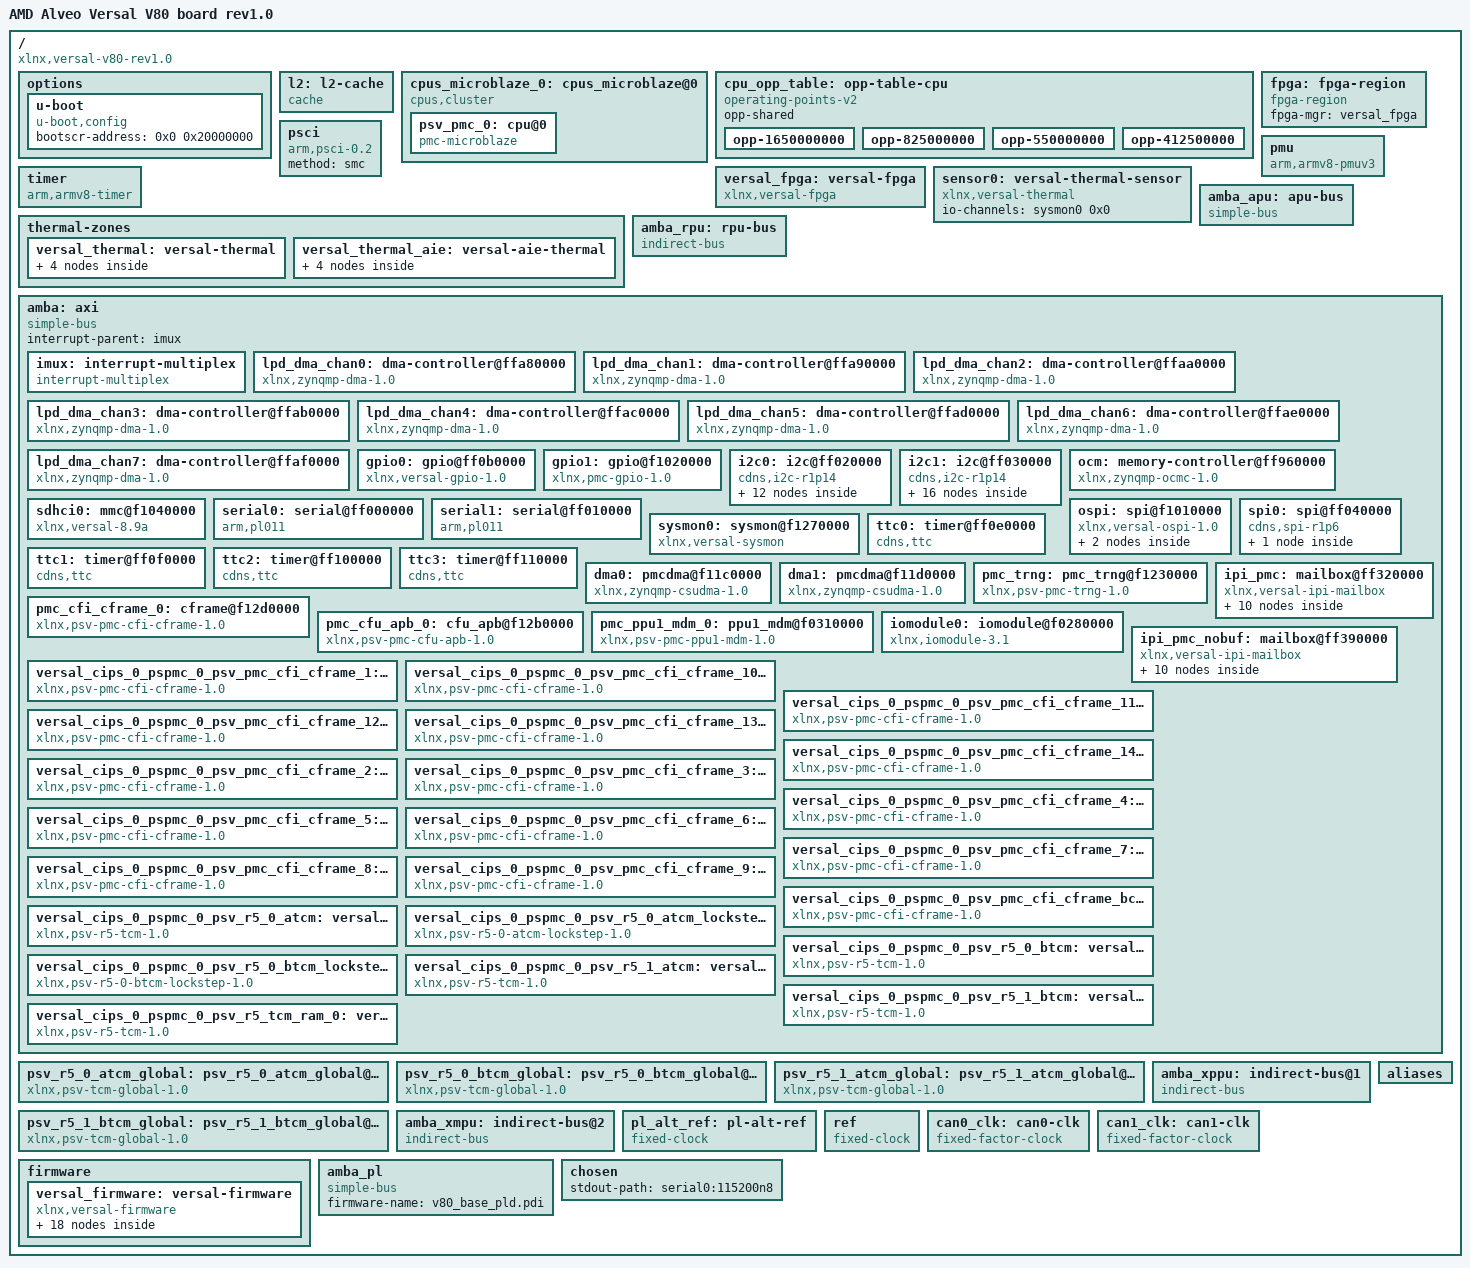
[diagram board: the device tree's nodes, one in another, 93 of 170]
/dts-v1/;
/ {
        compatible = "xlnx,versal-v80-rev1.0", "xlnx,versal";
        #address-cells = <0x2>;
        #size-cells = <0x2>;
        model = "AMD Alveo Versal V80 board rev1.0";
        board = "v80";
        device_id = "xcv80";
        slrcount = <0x3>;
        family = "Versal";
        speed_grade = "2MHP";
        pruned-sdt = <0x1>;

        options {

                u-boot {
                        compatible = "u-boot,config";
                        bootscr-address = <0x0 0x20000000>;
                };
        };

        l2: l2-cache {
                phandle = <0x88>;
                compatible = "cache";
                cache-level = <0x2>;
                cache-size = <0x100000>;
                cache-line-size = <0x40>;
                cache-sets = <0x1000>;
                cache-unified;
        };

        cpus_microblaze_0: cpus_microblaze@0 {
                phandle = <0xb1>;
                #address-cells = <0x1>;
                #size-cells = <0x0>;
                compatible = "cpus,cluster";
                address-map = <0xf0000000 &amba 0xf0000000 0x10000000>,
                 <0xff320000 &ipi_pmc 0xff320000 0x10000>,
                 <0xff390000 &ipi_pmc_nobuf 0xff390000 0x10000>,
                 <0xf0310000 &pmc_ppu1_mdm_0 0xf0310000 0x8000>,
                 <0xf1010000 &ospi 0xf1010000 0x10000>,
                 <0xf1020000 &gpio1 0xf1020000 0x10000>,
                 <0xf1040000 &sdhci0 0xf1040000 0x10000>,
                 <0xf11c0000 &dma0 0xf11c0000 0x10000>,
                 <0xf11d0000 &dma1 0xf11d0000 0x10000>,
                 <0xf1230000 &pmc_trng 0xf1230000 0x10000>,
                 <0xf1270000 &sysmon0 0xf1270000 0x30000>,
                 <0xf12b0000 &pmc_cfu_apb_0 0xf12b0000 0x10000>,
                 <0xf12d0000 &pmc_cfi_cframe_0 0xf12d0000 0x1000>,
                 <0xf12d2000 &versal_cips_0_pspmc_0_psv_pmc_cfi_cframe_1 0xf12d2000 0x1000>,
                 <0xf12d4000 &versal_cips_0_pspmc_0_psv_pmc_cfi_cframe_2 0xf12d4000 0x1000>,
                 <0xf12d6000 &versal_cips_0_pspmc_0_psv_pmc_cfi_cframe_3 0xf12d6000 0x1000>,
                 <0xf12d8000 &versal_cips_0_pspmc_0_psv_pmc_cfi_cframe_4 0xf12d8000 0x1000>,
                 <0xf12da000 &versal_cips_0_pspmc_0_psv_pmc_cfi_cframe_5 0xf12da000 0x1000>,
                 <0xf12dc000 &versal_cips_0_pspmc_0_psv_pmc_cfi_cframe_6 0xf12dc000 0x1000>,
                 <0xf12de000 &versal_cips_0_pspmc_0_psv_pmc_cfi_cframe_7 0xf12de000 0x1000>,
                 <0xf12e0000 &versal_cips_0_pspmc_0_psv_pmc_cfi_cframe_8 0xf12e0000 0x1000>,
                 <0xf12e2000 &versal_cips_0_pspmc_0_psv_pmc_cfi_cframe_9 0xf12e2000 0x1000>,
                 <0xf12e4000 &versal_cips_0_pspmc_0_psv_pmc_cfi_cframe_10 0xf12e4000 0x1000>,
                 <0xf12e6000 &versal_cips_0_pspmc_0_psv_pmc_cfi_cframe_11 0xf12e6000 0x1000>,
                 <0xf12e8000 &versal_cips_0_pspmc_0_psv_pmc_cfi_cframe_12 0xf12e8000 0x1000>,
                 <0xf12ea000 &versal_cips_0_pspmc_0_psv_pmc_cfi_cframe_13 0xf12ea000 0x1000>,
                 <0xf12ec000 &versal_cips_0_pspmc_0_psv_pmc_cfi_cframe_14 0xf12ec000 0x1000>,
                 <0xf12ee000 &versal_cips_0_pspmc_0_psv_pmc_cfi_cframe_bcast 0xf12ee000 0x1000>,
                 <0xff000000 &serial0 0xff000000 0x10000>,
                 <0xff010000 &serial1 0xff010000 0x10000>,
                 <0xff020000 &i2c0 0xff020000 0x10000>,
                 <0xff030000 &i2c1 0xff030000 0x10000>,
                 <0xff040000 &spi0 0xff040000 0x10000>,
                 <0xff0b0000 &gpio0 0xff0b0000 0x10000>,
                 <0xff0e0000 &ttc0 0xff0e0000 0x10000>,
                 <0xff0f0000 &ttc1 0xff0f0000 0x10000>,
                 <0xff100000 &ttc2 0xff100000 0x10000>,
                 <0xff110000 &ttc3 0xff110000 0x10000>,
                 <0xffa80000 &lpd_dma_chan0 0xffa80000 0x10000>,
                 <0xffa90000 &lpd_dma_chan1 0xffa90000 0x10000>,
                 <0xffaa0000 &lpd_dma_chan2 0xffaa0000 0x10000>,
                 <0xffab0000 &lpd_dma_chan3 0xffab0000 0x10000>,
                 <0xffac0000 &lpd_dma_chan4 0xffac0000 0x10000>,
                 <0xffad0000 &lpd_dma_chan5 0xffad0000 0x10000>,
                 <0xffae0000 &lpd_dma_chan6 0xffae0000 0x10000>,
                 <0xffaf0000 &lpd_dma_chan7 0xffaf0000 0x10000>,
                 <0xf0280000 &iomodule0 0xf0280000 0x1000>;
                #ranges-address-cells = <0x1>;
                #ranges-size-cells = <0x1>;

                psv_pmc_0: cpu@0 {
                        phandle = <0xb2>;
                        compatible = "pmc-microblaze";
                        device_type = "cpu";
                        reg = <0x0>;
                        operating-points-v2 = <&cpu_opp_table>;
                        xlnx,d-axi = <0x1>;
                        xlnx,addr-tag-bits = <0x0>;
                        xlnx,m-axi-dc-thread-id-width = <0x1>;
                        xlnx,m0-axis-protocol = "GENERIC";
                        xlnx,dcache-force-tag-lutram = <0x0>;
                        xlnx,interrupt-is-edge = <0x0>;
                        xlnx,use-mmu = <0x0>;
                        xlnx,m-axi-dp-exclusive-access = <0x0>;
                        xlnx,use-reorder-instr = <0x1>;
                        xlnx,m14-axis-protocol = "GENERIC";
                        xlnx,use-div = <0x1>;
                        xlnx,dc-axi-mon = <0x0>;
                        xlnx,m-axi-ic-user-signals = <0x0>;
                        xlnx,use-config-reset = <0x0>;
                        xlnx,s14-axis-protocol = "GENERIC";
                        xlnx,mmu-zones = <0x10>;
                        xlnx,enable-discrete-ports = <0x0>;
                        xlnx,d-lmb = <0x1>;
                        xlnx,m-axi-dc-exclusive-access = <0x0>;
                        xlnx,debug-interface = <0x0>;
                        xlnx,s9-axis-protocol = "GENERIC";
                        xlnx,sco = <0x0>;
                        xlnx,use-ext-brk = <0x0>;
                        xlnx,debug-enabled = <0x1>;
                        xlnx,daddr-size = <0x20>;
                        xlnx,s0-axis-data-width = <0x20>;
                        xlnx,use-extended-fsl-instr = <0x0>;
                        xlnx,m-axi-dc-user-signals = <0x0>;
                        xlnx,reset-msr = <0x0>;
                        xlnx,branch-target-cache-size = <0x0>;
                        xlnx,s2-axis-data-width = <0x20>;
                        xlnx,cache-byte-size = <0x2000>;
                        bus-handle = <0x1>;
                        xlnx,mmu-tlb-access = <0x3>;
                        xlnx,s4-axis-data-width = <0x20>;
                        xlnx,m-axi-ic-awuser-width = <0x5>;
                        xlnx,s6-axis-data-width = <0x20>;
                        xlnx,s4-axis-protocol = "GENERIC";
                        xlnx,s8-axis-data-width = <0x20>;
                        xlnx,edk-special = "microblaze";
                        xlnx,use-dcache = <0x0>;
                        xlnx,m-axi-dp-addr-width = <0x20>;
                        xlnx,m-axi-ic-wuser-width = <0x1>;
                        xlnx,i-axi = <0x0>;
                        xlnx,icache-streams = <0x0>;
                        xlnx,m-axi-dc-awuser-width = <0x5>;
                        xlnx,pss-ref-clk-freq = <0x1fca034>;
                        xlnx,use-stack-protection = <0x1>;
                        xlnx,m6-axis-protocol = "GENERIC";
                        xlnx,num-sync-ff-dbg-clk = <0x1>;
                        xlnx,m-axi-ip-data-width = <0x20>;
                        d-cache-size = <0x2000>;
                        xlnx,use-pcmp-instr = <0x1>;
                        xlnx,area-optimized = <0x0>;
                        xlnx,avoid-primitives = <0x0>;
                        xlnx,m1-axis-protocol = "GENERIC";
                        xlnx,i-lmb = <0x1>;
                        xlnx,lockstep-select = <0x0>;
                        xlnx,dcache-data-width = <0x0>;
                        xlnx,icache-force-tag-lutram = <0x0>;
                        xlnx,m15-axis-protocol = "GENERIC";
                        xlnx,use-branch-target-cache = <0x0>;
                        xlnx,m-axi-ip-thread-id-width = <0x1>;
                        xlnx,mmu-itlb-size = <0x2>;
                        xlnx,number-of-pc-brk = <0x2>;
                        xlnx,imprecise-exceptions = <0x0>;
                        xlnx,m-axi-ic-buser-width = <0x1>;
                        xlnx,m-axi-ic-addr-width = <0x20>;
                        xlnx,s15-axis-protocol = "GENERIC";
                        d-cache-highaddr = <0x3fffffff>;
                        xlnx,m10-axis-protocol = "GENERIC";
                        xlnx,optimization = <0x0>;
                        xlnx,m-axi-ic-aruser-width = <0x5>;
                        xlnx,d-lmb-mon = <0x0>;
                        xlnx,s10-axis-protocol = "GENERIC";
                        xlnx,m-axi-ic-ruser-width = <0x1>;
                        xlnx,s5-axis-protocol = "GENERIC";
                        xlnx,fault-tolerant = <0x1>;
                        d-cache-line-size = <0x10>;
                        xlnx,m-axi-dc-aruser-width = <0x5>;
                        xlnx,mmu-privileged-instr = <0x0>;
                        xlnx,m-axi-i-bus-exception = <0x0>;
                        xlnx,reset-msr-eip = <0x0>;
                        xlnx,endianness = <0x1>;
                        xlnx,reset-msr-ice = <0x0>;
                        xlnx,dp-axi-mon = <0x0>;
                        xlnx,s10-axis-data-width = <0x20>;
                        xlnx,s0-axis-protocol = "GENERIC";
                        xlnx,s12-axis-data-width = <0x20>;
                        xlnx,m7-axis-protocol = "GENERIC";
                        xlnx,s14-axis-data-width = <0x20>;
                        xlnx,m-axi-d-bus-exception = <0x1>;
                        xlnx,reset-msr-bip = <0x1>;
                        xlnx,debug-external-trace = <0x0>;
                        xlnx,addr-size = <0x20>;
                        xlnx,m-axi-ic-user-value = <0x1f>;
                        xlnx,m1-axis-data-width = <0x20>;
                        xlnx,debug-event-counters = <0x5>;
                        xlnx,m3-axis-data-width = <0x20>;
                        xlnx,fpu-exception = <0x0>;
                        xlnx,m2-axis-protocol = "GENERIC";
                        xlnx,m5-axis-data-width = <0x20>;
                        xlnx,m7-axis-data-width = <0x20>;
                        xlnx,edk-iptype = "PROCESSOR";
                        xlnx,debug-latency-counters = <0x1>;
                        xlnx,interconnect = <0x2>;
                        xlnx,m9-axis-data-width = <0x20>;
                        xlnx,edge-is-positive = <0x1>;
                        xlnx,use-icache = <0x0>;
                        xlnx,async-wakeup = <0x3>;
                        xlnx,m10-axis-data-width = <0x20>;
                        xlnx,m12-axis-data-width = <0x20>;
                        xlnx,use-ext-nm-brk = <0x0>;
                        xlnx,m11-axis-protocol = "GENERIC";
                        xlnx,m14-axis-data-width = <0x20>;
                        xlnx,icache-always-used = <0x0>;
                        xlnx,ic-axi-mon = <0x0>;
                        xlnx,num-sync-ff-clk-irq = <0x1>;
                        xlnx,freq = <0x1312d000>;
                        xlnx,lockstep-master = <0x0>;
                        xlnx,s11-axis-protocol = "GENERIC";
                        xlnx,use-msr-instr = <0x1>;
                        xlnx,s6-axis-protocol = "GENERIC";
                        xlnx,iaddr-size = <0x20>;
                        xlnx,interrupt-mon = <0x0>;
                        xlnx,m-axi-dc-data-width = <0x20>;
                        xlnx,dynamic-bus-sizing = <0x0>;
                        xlnx,number-of-wr-addr-brk = <0x1>;
                        xlnx,use-interrupt = <0x1>;
                        xlnx,m-axi-ip-addr-width = <0x20>;
                        xlnx,async-interrupt = <0x1>;
                        xlnx,pc-width = <0x20>;
                        xlnx,icache-victims = <0x0>;
                        xlnx,reset-msr-ee = <0x0>;
                        xlnx,s1-axis-protocol = "GENERIC";
                        xlnx,m8-axis-protocol = "GENERIC";
                        i-cache-baseaddr = <0x0>;
                        xlnx,i-lmb-mon = <0x0>;
                        xlnx,dcache-byte-size = <0x2000>;
                        xlnx,m-axi-dp-thread-id-width = <0x1>;
                        xlnx,data-size = <0x20>;
                        xlnx,m-axi-dc-wuser-width = <0x1>;
                        xlnx,fsl-exception = <0x0>;
                        xlnx,m3-axis-protocol = "GENERIC";
                        xlnx,s1-axis-data-width = <0x20>;
                        xlnx,dcache-use-writeback = <0x0>;
                        xlnx,div-zero-exception = <0x1>;
                        xlnx,s3-axis-data-width = <0x20>;
                        xlnx,base-vectors = <0xf0240000>;
                        xlnx,icache-line-len = <0x4>;
                        xlnx,s5-axis-data-width = <0x20>;
                        xlnx,s7-axis-data-width = <0x20>;
                        xlnx,allow-dcache-wr = <0x1>;
                        xlnx,s9-axis-data-width = <0x20>;
                        xlnx,use-barrel = <0x1>;
                        xlnx,g-use-exceptions = <0x1>;
                        xlnx,dcache-line-len = <0x4>;
                        xlnx,m12-axis-protocol = "GENERIC";
                        xlnx,num-sync-ff-clk = <0x2>;
                        i-cache-size = <0x2000>;
                        xlnx,instance = "design_1_microblaze_0_0";
                        xlnx,reset-msr-ie = <0x0>;
                        xlnx,s12-axis-protocol = "GENERIC";
                        xlnx,dcache-addr-tag = <0x0>;
                        xlnx,m-axi-ic-thread-id-width = <0x1>;
                        xlnx,number-of-rd-addr-brk = <0x1>;
                        xlnx,m-axi-dc-buser-width = <0x1>;
                        xlnx,s7-axis-protocol = "GENERIC";
                        xlnx,lockstep-slave = <0x0>;
                        xlnx,debug-profile-size = <0x0>;
                        xlnx,s2-axis-protocol = "GENERIC";
                        xlnx,m9-axis-protocol = "GENERIC";
                        xlnx,debug-counter-width = <0x20>;
                        xlnx,icache-data-width = <0x0>;
                        xlnx,m-axi-dc-ruser-width = <0x1>;
                        xlnx,reset-msr-dce = <0x0>;
                        xlnx,ip-name = "psv_pmc";
                        xlnx,ip-axi-mon = <0x0>;
                        xlnx,m-axi-dp-data-width = <0x20>;
                        xlnx,m4-axis-protocol = "GENERIC";
                        xlnx,dcache-always-used = <0x0>;
                        xlnx,ill-opcode-exception = <0x1>;
                        xlnx,trace = <0x1>;
                        xlnx,pvr = <0x2>;
                        xlnx,debug-trace-size = <0x2000>;
                        i-cache-line-size = <0x10>;
                        xlnx,m13-axis-protocol = "GENERIC";
                        xlnx,s11-axis-data-width = <0x20>;
                        xlnx,m-axi-dc-addr-width = <0x20>;
                        xlnx,s13-axis-data-width = <0x20>;
                        xlnx,ecc-use-ce-exception = <0x0>;
                        xlnx,opcode-0x0-illegal = <0x1>;
                        xlnx,pvr-user2 = <0x0>;
                        xlnx,s15-axis-data-width = <0x20>;
                        xlnx,s13-axis-protocol = "GENERIC";
                        xlnx,m0-axis-data-width = <0x20>;
                        i-cache-highaddr = <0x3fffffff>;
                        xlnx,s8-axis-protocol = "GENERIC";
                        xlnx,m2-axis-data-width = <0x20>;
                        xlnx,num-sync-ff-clk-debug = <0x2>;
                        xlnx,allow-icache-wr = <0x1>;
                        xlnx,m4-axis-data-width = <0x20>;
                        xlnx,g-template-list = <0x0>;
                        xlnx,m6-axis-data-width = <0x20>;
                        xlnx,m-axi-ic-data-width = <0x20>;
                        xlnx,m8-axis-data-width = <0x20>;
                        xlnx,use-hw-mul = <0x2>;
                        xlnx,use-fpu = <0x0>;
                        xlnx,s3-axis-protocol = "GENERIC";
                        xlnx,use-non-secure = <0x0>;
                        d-cache-baseaddr = <0x0>;
                        xlnx,m11-axis-data-width = <0x20>;
                        xlnx,m13-axis-data-width = <0x20>;
                        xlnx,instr-size = <0x20>;
                        xlnx,m15-axis-data-width = <0x20>;
                        xlnx,mmu-dtlb-size = <0x4>;
                        xlnx,fsl-links = <0x0>;
                        xlnx,m5-axis-protocol = "GENERIC";
                        xlnx,dcache-victims = <0x0>;
                        xlnx,m-axi-dc-user-value = <0x1f>;
                        xlnx,unaligned-exceptions = <0x1>;
                };
        };

        cpu_opp_table: opp-table-cpu {
                phandle = <0x85>;
                compatible = "operating-points-v2";
                opp-shared;

                opp-1650000000 {
                        opp-hz = <0x0 0x62590080>;
                        clock-latency-ns = <0x7a120>;
                        opp-microvolt = <0xf4240>;
                };

                opp-825000000 {
                        opp-hz = <0x0 0x312c8040>;
                        clock-latency-ns = <0x7a120>;
                        opp-microvolt = <0xf4240>;
                };

                opp-550000000 {
                        opp-hz = <0x0 0x20c85580>;
                        clock-latency-ns = <0x7a120>;
                        opp-microvolt = <0xf4240>;
                };

                opp-412500000 {
                        opp-hz = <0x0 0x18964020>;
                        clock-latency-ns = <0x7a120>;
                        opp-microvolt = <0xf4240>;
                };
        };

        fpga: fpga-region {
                phandle = <0xba>;
                compatible = "fpga-region";
                fpga-mgr = <&versal_fpga>;
                #address-cells = <0x2>;
                #size-cells = <0x2>;
        };

        psci: psci {
                phandle = <0xbb>;
                compatible = "arm,psci-0.2";
                method = "smc";
        };

        pmu {
                compatible = "arm,armv8-pmuv3";
                interrupt-parent = <&imux>;
                interrupts = <0x1 0x7 0x304>;
        };

        timer: timer {
                phandle = <0xbc>;
                compatible = "arm,armv8-timer";
                interrupt-parent = <&imux>;
                interrupts = <0x1 0xd 0x4 0x1 0xe 0x4 0x1 0xb 0x4 0x1 0xa 0x4>;
        };

        versal_fpga: versal-fpga {
                phandle = <0xa2>;
                compatible = "xlnx,versal-fpga";
        };

        sensor0: versal-thermal-sensor {
                phandle = <0xa4>;
                compatible = "xlnx,versal-thermal";
                #thermal-sensor-cells = <0x1>;
                io-channels = <&sysmon0 0x0>;
                io-channel-names = "sysmon-temp-channel";
        };

        thermal-zones {

                versal_thermal: versal-thermal {
                        phandle = <0xbd>;
                        polling-delay-passive = <0xfa>;
                        polling-delay = <0x3e8>;
                        thermal-sensors = <&sensor0 0x0>;

                        trips {

                                temp_alert: temp-alert {
                                        phandle = <0xbe>;
                                        temperature = <0x11170>;
                                        hysteresis = <0x0>;
                                        type = "passive";
                                };

                                ot_crit: ot-crit {
                                        phandle = <0xbf>;
                                        temperature = <0x1e848>;
                                        hysteresis = <0x0>;
                                        type = "critical";
                                };
                        };

                        cooling-maps {
                        };
                };

                versal_thermal_aie: versal-aie-thermal {
                        phandle = <0xc0>;
                        polling-delay-passive = <0xfa>;
                        polling-delay = <0x3e8>;
                        thermal-sensors = <&sensor0 0x1>;

                        trips {

                                temp_alert_aie: temp-alert-aie {
                                        phandle = <0xc1>;
                                        temperature = <0x11170>;
                                        hysteresis = <0x0>;
                                        type = "passive";
                                };

                                ot_crit_aie: ot-crit-aie {
                                        phandle = <0xc2>;
                                        temperature = <0x1e848>;
                                        hysteresis = <0x0>;
                                        type = "critical";
                                };
                        };

                        cooling-maps {
                        };
                };
        };

        amba_apu: apu-bus {
                phandle = <0x2>;
                compatible = "simple-bus";
                #address-cells = <0x2>;
                #size-cells = <0x2>;
                ranges;
                bootph-all;
        };

        amba_rpu: rpu-bus {
                phandle = <0x93>;
                compatible = "indirect-bus";
                #address-cells = <0x2>;
                #size-cells = <0x2>;
                ranges;
                bootph-all;
        };

        amba: axi {
                phandle = <0x1>;
                compatible = "simple-bus";
                #address-cells = <0x2>;
                #size-cells = <0x2>;
                ranges;
                interrupt-parent = <&imux>;
                bootph-all;

                imux: interrupt-multiplex {
                        phandle = <0xa3>;
                        compatible = "interrupt-multiplex";
                        #address-cells = <0x0>;
                        #interrupt-cells = <0x3>;
                        interrupt-controller;
                        interrupt-map-mask = <0x0 0xffff 0x0>;
                        interrupt-map = <0x55 0x0 0x15 &amba 0x0>,
                         <0x0 0x55 0x0 &sysmon0 0x4>,
                         <0x3e 0x4 0x0 &pmc_cfu_apb_0 0x0>,
                         <0x0 0x55 0x0 &versal_cips_0_pspmc_0_psv_pmc_cfi_cframe_2 0x4>,
                         <0x0 0x55 0x0 &lpd_dma_chan1 0x4>,
                         <0x0 0x55 0x0 &lpd_dma_chan5 0x4>,
                         <0x0 0x55 0x0 &lpd_dma_chan3 0x4>,
                         <0x4a 0x4 0x0 &versal_cips_0_pspmc_0_psv_pmc_cfi_cframe_8 0x0>,
                         <0x0 0x55 0x0 &psv_r5_1_atcm_global 0x4>,
                         <0x99 0x0 0x14 &amba 0x0>,
                         <0x0 0x99 0x0 &versal_cips_0_pspmc_0_psv_pmc_cfi_cframe_1 0x4>,
                         <0x42 0x4 0x0 &versal_cips_0_pspmc_0_psv_pmc_cfi_cframe_3 0x0>,
                         <0x7e 0x4 0x0 &lpd_dma_chan7 0x0>,
                         <0x0 0x99 0x0 &ttc0 0x4>,
                         <0x7c 0x4 0x0 &lpd_dma_chan4 0x0>,
                         <0x1a 0x4 0x0 &versal_cips_0_pspmc_0_psv_pmc_cfi_cframe_10 0x0>,
                         <0x83 0x4 0x0 &psv_r5_1_btcm_global 0x0>;
                };

                lpd_dma_chan0: dma-controller@ffa80000 {
                        phandle = <0x79>;
                        compatible = "xlnx,zynqmp-dma-1.0";
                        status = "okay";
                        reg = <0x0 0xffa80000 0x0 0x1000>;
                        interrupts = <0x0 0x3c 0x4>;
                        interrupt-parent = <&imux>;
                        clock-names = "clk_main", "clk_apb";
                        xlnx,dma-type = <0x1>;
                        #dma-cells = <0x1>;
                        xlnx,bus-width = <0x40>;
                        clocks = <&versal_clk 0x51>,
                         <&versal_clk 0x52>;
                        power-domains = <&versal_firmware 0x18224035>;
                        xlnx,is-cache-coherent = <0x0>;
                        xlnx,ip-name = "psv_adma";
                        xlnx,dma-mode = <0x1>;
                        xlnx,name = "versal_cips_0_pspmc_0_psv_adma_0";
                };

                lpd_dma_chan1: dma-controller@ffa90000 {
                        phandle = <0x7a>;
                        compatible = "xlnx,zynqmp-dma-1.0";
                        status = "okay";
                        reg = <0x0 0xffa90000 0x0 0x1000>;
                        interrupts = <0x0 0x3d 0x4>;
                        interrupt-parent = <&imux>;
                        clock-names = "clk_main", "clk_apb";
                        xlnx,dma-type = <0x1>;
                        #dma-cells = <0x1>;
                        xlnx,bus-width = <0x40>;
                        clocks = <&versal_clk 0x51>,
                         <&versal_clk 0x52>;
                        power-domains = <&versal_firmware 0x18224036>;
                        xlnx,is-cache-coherent = <0x0>;
                        xlnx,ip-name = "psv_adma";
                        xlnx,dma-mode = <0x1>;
                        xlnx,name = "versal_cips_0_pspmc_0_psv_adma_1";
                };

                lpd_dma_chan2: dma-controller@ffaa0000 {
                        phandle = <0x7b>;
                        compatible = "xlnx,zynqmp-dma-1.0";
                        status = "okay";
                        reg = <0x0 0xffaa0000 0x0 0x1000>;
                        interrupts = <0x0 0x3e 0x4>;
                        interrupt-parent = <&imux>;
                        clock-names = "clk_main", "clk_apb";
                        xlnx,dma-type = <0x1>;
                        #dma-cells = <0x1>;
                        xlnx,bus-width = <0x40>;
                        clocks = <&versal_clk 0x51>,
                         <&versal_clk 0x52>;
                        power-domains = <&versal_firmware 0x18224037>;
                        xlnx,is-cache-coherent = <0x0>;
                        xlnx,ip-name = "psv_adma";
                        xlnx,dma-mode = <0x1>;
                        xlnx,name = "versal_cips_0_pspmc_0_psv_adma_2";
                };

                lpd_dma_chan3: dma-controller@ffab0000 {
                        phandle = <0x7c>;
                        compatible = "xlnx,zynqmp-dma-1.0";
                        status = "okay";
                        reg = <0x0 0xffab0000 0x0 0x1000>;
                        interrupts = <0x0 0x3f 0x4>;
                        interrupt-parent = <&imux>;
                        clock-names = "clk_main", "clk_apb";
                        xlnx,dma-type = <0x1>;
                        #dma-cells = <0x1>;
                        xlnx,bus-width = <0x40>;
                        clocks = <&versal_clk 0x51>,
                         <&versal_clk 0x52>;
                        power-domains = <&versal_firmware 0x18224038>;
                        xlnx,is-cache-coherent = <0x0>;
                        xlnx,ip-name = "psv_adma";
                        xlnx,dma-mode = <0x1>;
                        xlnx,name = "versal_cips_0_pspmc_0_psv_adma_3";
                };

                lpd_dma_chan4: dma-controller@ffac0000 {
                        phandle = <0x7d>;
                        compatible = "xlnx,zynqmp-dma-1.0";
                        status = "okay";
                        reg = <0x0 0xffac0000 0x0 0x1000>;
                        interrupts = <0x0 0x40 0x4>;
                        interrupt-parent = <&imux>;
                        clock-names = "clk_main", "clk_apb";
                        xlnx,dma-type = <0x1>;
                        #dma-cells = <0x1>;
                        xlnx,bus-width = <0x40>;
                        clocks = <&versal_clk 0x51>,
                         <&versal_clk 0x52>;
                        power-domains = <&versal_firmware 0x18224039>;
                        xlnx,is-cache-coherent = <0x0>;
                        xlnx,ip-name = "psv_adma";
                        xlnx,dma-mode = <0x1>;
                        xlnx,name = "versal_cips_0_pspmc_0_psv_adma_4";
                };

                lpd_dma_chan5: dma-controller@ffad0000 {
                        phandle = <0x7e>;
                        compatible = "xlnx,zynqmp-dma-1.0";
                        status = "okay";
                        reg = <0x0 0xffad0000 0x0 0x1000>;
                        interrupts = <0x0 0x41 0x4>;
                        interrupt-parent = <&imux>;
                        clock-names = "clk_main", "clk_apb";
                        xlnx,dma-type = <0x1>;
                        #dma-cells = <0x1>;
                        xlnx,bus-width = <0x40>;
                        clocks = <&versal_clk 0x51>,
                         <&versal_clk 0x52>;
                        power-domains = <&versal_firmware 0x1822403a>;
                        xlnx,is-cache-coherent = <0x0>;
                        xlnx,ip-name = "psv_adma";
                        xlnx,dma-mode = <0x1>;
                        xlnx,name = "versal_cips_0_pspmc_0_psv_adma_5";
                };

                lpd_dma_chan6: dma-controller@ffae0000 {
                        phandle = <0x7f>;
                        compatible = "xlnx,zynqmp-dma-1.0";
                        status = "okay";
                        reg = <0x0 0xffae0000 0x0 0x1000>;
                        interrupts = <0x0 0x42 0x4>;
                        interrupt-parent = <&imux>;
                        clock-names = "clk_main", "clk_apb";
                        xlnx,dma-type = <0x1>;
                        #dma-cells = <0x1>;
                        xlnx,bus-width = <0x40>;
                        clocks = <&versal_clk 0x51>,
                         <&versal_clk 0x52>;
                        power-domains = <&versal_firmware 0x1822403b>;
                        xlnx,is-cache-coherent = <0x0>;
                        xlnx,ip-name = "psv_adma";
                        xlnx,dma-mode = <0x1>;
                        xlnx,name = "versal_cips_0_pspmc_0_psv_adma_6";
                };

                lpd_dma_chan7: dma-controller@ffaf0000 {
                        phandle = <0x80>;
                        compatible = "xlnx,zynqmp-dma-1.0";
                        status = "okay";
                        reg = <0x0 0xffaf0000 0x0 0x1000>;
                        interrupts = <0x0 0x43 0x4>;
                        interrupt-parent = <&imux>;
                        clock-names = "clk_main", "clk_apb";
                        xlnx,dma-type = <0x1>;
                        #dma-cells = <0x1>;
                        xlnx,bus-width = <0x40>;
                        clocks = <&versal_clk 0x51>,
                         <&versal_clk 0x52>;
                        power-domains = <&versal_firmware 0x1822403c>;
                        xlnx,is-cache-coherent = <0x0>;
                        xlnx,ip-name = "psv_adma";
                        xlnx,dma-mode = <0x1>;
                        xlnx,name = "versal_cips_0_pspmc_0_psv_adma_7";
                };

                gpio0: gpio@ff0b0000 {
                        phandle = <0x6a>;
                        compatible = "xlnx,versal-gpio-1.0";
                        status = "okay";
                        reg = <0x0 0xff0b0000 0x0 0x1000>;
                        interrupts = <0x0 0xd 0x4>;
                        interrupt-parent = <&imux>;
                        #gpio-cells = <0x2>;
                        gpio-controller;
                        #interrupt-cells = <0x2>;
                        interrupt-controller;
                        clocks = <&versal_clk 0x52>;
                        power-domains = <&versal_firmware 0x18224023>;
                        xlnx,ip-name = "psv_gpio";
                        emio-gpio-width = "";
                        xlnx,name = "versal_cips_0_pspmc_0_psv_gpio_2";
                        gpio-line-names = "I2C_QSFP_SCL", "I2C_QSFP_SDA", "I2C_MAIN_SCL", "I2C_MAIN_SDA", "I2C_MAIN_RST_B", "I2C_MAIN_INTR_B", "QSFP4_IOEXP_RST", "QSFP3_IOEXP_RST", "LPD_UART0_RXD", "LPD_UART0_TXD", "", "", "SPI0_SCLK", "I2C_QSFP_RST_B", "I2C_QSFP_INTR_B", "SPI0_CS_B", "SPI0_MISO", "SPI0_MOSI", "QSFP1_IOEXP_RST", "QSFP2_IOEXP_RST", "LPD_UART1_TXD", "LPD_UART1_RXD", "BOARD_STATUS_LED_R", "BOARD_STATUS_LED_G", "BOARD_STATUS_LED_B", "", "", "", "", "", "", "", "", "", "", "", "", "", "", "", "", "", "", "", "", "", "", "", "", "", "", "", "", "", "", "", "", "";
                };

                gpio1: gpio@f1020000 {
                        phandle = <0x2c>;
                        compatible = "xlnx,pmc-gpio-1.0";
                        status = "okay";
                        reg = <0x0 0xf1020000 0x0 0x1000>;
                        interrupts = <0x0 0x7a 0x4>;
                        interrupt-parent = <&imux>;
                        #gpio-cells = <0x2>;
                        gpio-controller;
                        #interrupt-cells = <0x2>;
                        interrupt-controller;
                        clocks = <&versal_clk 0x3d>;
                        power-domains = <&versal_firmware 0x1822402c>;
                        xlnx,ip-name = "psv_pmc_gpio";
                        xlnx,name = "versal_cips_0_pspmc_0_psv_pmc_gpio_0";
                        gpio-line-names = "", "", "", "", "", "", "", "", "", "", "", "BOARD_ID", "OSPI_RESET_B", "", "", "", "", "", "", "", "", "", "", "", "PCIE_RST1_B", "PCIE_RST2_B", "QSFP4_ACT_LED", "QSFP4_LNK_GR_LED", "QSFP4_LNK_YL_LED", "EN_3V3_MCIO", "QSFP3_ACT_LED", "QSFP3_LNK_GR_LED", "QSFP3_LNK_YL_LED", "PG_3V3_MCIO", "QSFP1_ACT_LED", "QSFP1_LNK_GR_LED", "QSFP1_LNK_YL_LED", "", "QSFP2_ACT_LED", "QSFP2_LNK_GR_LED", "QSFP2_LNK_YL_LED", "PG_12V_AUX2", "PCIE_EXP1_PERSTB", "PCIE_EXP2_PERSTB", "PCIE_EXP3_PERSTB", "MCIO_P2_FLEXIO0_BUF", "PMC_UART1_TXD", "PMC_UART1_RXD", "PCIE_EXP1_CPRSNTB", "PCIE_EXP2_CPRSNTB", "PCIE_EXP3_CPRSNTB", "USB_PRES", "", "", "", "", "", "", "", "", "", "", "", "", "", "", "", "", "", "", "", "", "", "", "", "", "", "", "", "", "", "", "", "", "", "", "", "", "", "", "", "", "", "", "", "", "", "", "", "", "", "", "", "", "", "", "", "", "", "", "", "", "", "", "", "";
                };

                i2c0: i2c@ff020000 {
                        phandle = <0x65>;
                        compatible = "cdns,i2c-r1p14";
                        status = "okay";
                        reg = <0x0 0xff020000 0x0 0x1000>;
                        interrupts = <0x0 0xe 0x4>;
                        interrupt-parent = <&imux>;
                        clock-frequency = <0x186a0>;
                        #address-cells = <0x1>;
                        #size-cells = <0x0>;
                        clocks = <&versal_clk 0x62>;
                        power-domains = <&versal_firmware 0x1822401d>;
                        xlnx,clock-freq = <0x5f5e0a4>;
                        xlnx,i2c-clk-freq-hz = <0x5f5e0a4>;
                        xlnx,ip-name = "psv_i2c";
                        xlnx,iic-board-interface = "custom";
                        xlnx,name = "versal_cips_0_pspmc_0_psv_i2c_0";

                        regulator_u50: regulator@60 {
                                phandle = <0xc8>;
                                compatible = "isil,isl68224";
                                reg = <0x60>;
                        };

                        regulator_uXX: regulator@61 {
                                phandle = <0xc9>;
                                compatible = "isil,isl68224";
                                reg = <0x61>;
                        };

                        sensor_u30: temp-sensor@1a {
                                phandle = <0xca>;
                                compatible = "onnn,cat34ts02", "jedec,jc-42.4-temp";
                                reg = <0x1a>;
                        };

                        gpio_u43: gpio@20 {
                                phandle = <0xcb>;
                                compatible = "ti,tca6416";
                                reg = <0x20>;
                                gpio-controller;
                                #gpio-cells = <0x2>;
                                interrupt-parent = <&gpio0>;
                                interrupts = <0x5 0x1>;
                                gpio-line-names = "TCRITn", "EN_VCC_FUSE", "FRU_EEPRM_WP", "PCIE_SMB_LT_EN", "IOEXP_POR_B", "CG_CONFI_GPIO0", "EN_DIMM", "DMB_PRSNT_B", "12V_AUX1_SENSE0_N", "12V_AUX1_SENSE1_N", "12V_AUX2_SENSE0_N", "12V_AUX2_SENSE1_N", "PG_3V3_QSFP", "DIMM_PWRGD", "BRD_PWRGD", "HBM_PWRGD";
                        };

                        ina_u48: power-sensor@40 {
                                phandle = <0xcc>;
                                compatible = "ti,ina3221";
                                reg = <0x40>;
                                #address-cells = <0x1>;
                                #size-cells = <0x0>;

                                input@0 {
                                        reg = <0x0>;
                                        label = "VR_12V";
                                        shunt-resistor-micro-ohms = <0x7d0>;
                                };

                                input@1 {
                                        reg = <0x1>;
                                        label = "VR_3V3";
                                        shunt-resistor-micro-ohms = <0x7d0>;
                                };

                                input@2 {
                                        reg = <0x2>;
                                        label = "VR_3V3_QSFP";
                                        shunt-resistor-micro-ohms = <0x7d0>;
                                };
                        };

                        ina_u49: power-sensor@41 {
                                phandle = <0xcd>;
                                compatible = "ti,ina3221";
                                reg = <0x41>;
                                #address-cells = <0x1>;
                                #size-cells = <0x0>;

                                input@0 {
                                        reg = <0x0>;
                                        label = "VR_1V2_VCCO_DIMM";
                                        shunt-resistor-micro-ohms = <0x7d0>;
                                };

                                input@1 {
                                        reg = <0x1>;
                                        label = "VR_12V_AUX1";
                                        shunt-resistor-micro-ohms = <0x7d0>;
                                };

                                input@2 {
                                        reg = <0x2>;
                                        label = "VR_12V_AUX2";
                                        shunt-resistor-micro-ohms = <0x7d0>;
                                };
                        };
                };

                i2c1: i2c@ff030000 {
                        phandle = <0x66>;
                        compatible = "cdns,i2c-r1p14";
                        status = "okay";
                        reg = <0x0 0xff030000 0x0 0x1000>;
                        interrupts = <0x0 0xf 0x4>;
                        interrupt-parent = <&imux>;
                        clock-frequency = <0x186a0>;
                        #address-cells = <0x1>;
                        #size-cells = <0x0>;
                        clocks = <&versal_clk 0x63>;
                        power-domains = <&versal_firmware 0x1822401e>;
                        xlnx,clock-freq = <0x5f5e0a4>;
                        xlnx,i2c-clk-freq-hz = <0x5f5e0a4>;
                        xlnx,ip-name = "psv_i2c";
                        xlnx,iic-board-interface = "custom";
                        xlnx,name = "versal_cips_0_pspmc_0_psv_i2c_1";

                        qsfp_power: gpio@21 {
                                phandle = <0xce>;
                                compatible = "ti,tca6408";
                                reg = <0x21>;
                                gpio-controller;
                                #gpio-cells = <0x2>;
                                interrupt-parent = <&gpio0>;
                                interrupts = <0xe 0x1>;
                                gpio-line-names = "EN_3V3_QSFP1", "EN_3V3_QSFP2", "EN_3V3_QSFP3", "EN_3V3_QSFP4", "PG_3V3_QSFP1", "PG_3V3_QSFP2", "PG_3V3_QSFP3", "PG_3V3_QSFP4";
                        };

                        i2c_qsfp1: i2c-mux@70 {
                                phandle = <0xa7>;
                                compatible = "nxp,pca9545";
                                #address-cells = <0x1>;
                                #size-cells = <0x0>;
                                #interrupt-cells = <0x2>;
                                reg = <0x70>;
                                interrupt-parent = <&gpio0>;
                                interrupts = <0xe 0x1>;
                                interrupt-controller;

                                i2c@0 {
                                        #address-cells = <0x1>;
                                        #size-cells = <0x0>;
                                        reg = <0x0>;

                                        qsfp1: gpio@20 {
                                                phandle = <0xcf>;
                                                compatible = "ti,tca6408";
                                                reg = <0x20>;
                                                gpio-controller;
                                                #gpio-cells = <0x2>;
                                                interrupt-parent = <&i2c_qsfp1>;
                                                interrupts = <0x2 0x1>;
                                                gpio-line-names = "QSFP1_MODSELL", "QSFP1_RESETL", "QSFP1_LPMODE", "QSFP1_MODPRSL", "QSFP1_INTR_B", "", "", "";
                                        };
                                };

                                i2c@1 {
                                        #address-cells = <0x1>;
                                        #size-cells = <0x0>;
                                        reg = <0x1>;
                                };

                                i2c@2 {
                                        #address-cells = <0x1>;
                                        #size-cells = <0x0>;
                                        reg = <0x2>;

                                        qsfp2: gpio@20 {
                                                phandle = <0xd0>;
                                                compatible = "ti,tca6408";
                                                reg = <0x20>;
                                                gpio-controller;
                                                #gpio-cells = <0x2>;
                                                interrupt-parent = <&i2c_qsfp1>;
                                                interrupts = <0x2 0x1>;
                                                gpio-line-names = "QSFP2_MODSELL", "QSFP2_RESETL", "QSFP2_LPMODE", "QSFP2_MODPRSL", "QSFP2_INTR_B", "", "", "";
                                        };
                                };

                                i2c@3 {
                                        #address-cells = <0x1>;
                                        #size-cells = <0x0>;
                                        reg = <0x3>;
                                };
                        };

                        i2c_qsfp3: i2c-mux@71 {
                                phandle = <0xa8>;
                                compatible = "nxp,pca9545";
                                #address-cells = <0x1>;
                                #size-cells = <0x0>;
                                #interrupt-cells = <0x2>;
                                reg = <0x70>;
                                interrupt-parent = <&gpio0>;
                                interrupts = <0xe 0x1>;
                                interrupt-controller;

                                i2c@0 {
                                        #address-cells = <0x1>;
                                        #size-cells = <0x0>;
                                        reg = <0x0>;

                                        qsfp3: gpio@20 {
                                                phandle = <0xd1>;
                                                compatible = "ti,tca6408";
                                                reg = <0x20>;
                                                gpio-controller;
                                                #gpio-cells = <0x2>;
                                                interrupt-parent = <&i2c_qsfp3>;
                                                interrupts = <0x2 0x1>;
                                                gpio-line-names = "QSFP3_MODSELL", "QSFP3_RESETL", "QSFP3_LPMODE", "QSFP3_MODPRSL", "QSFP3_INTR_B", "", "", "";
                                        };
                                };

                                i2c@1 {
                                        #address-cells = <0x1>;
                                        #size-cells = <0x0>;
                                        reg = <0x1>;
                                };

                                i2c@2 {
                                        #address-cells = <0x1>;
                                        #size-cells = <0x0>;
                                        reg = <0x2>;

                                        qsfp4: gpio@20 {
                                                phandle = <0xd2>;
                                                compatible = "ti,tca6408";
                                                reg = <0x20>;
                                                gpio-controller;
                                                #gpio-cells = <0x2>;
                                                interrupt-parent = <&i2c_qsfp3>;
                                                interrupts = <0x2 0x1>;
                                                gpio-line-names = "QSFP4_MODSELL", "QSFP4_RESETL", "QSFP4_LPMODE", "QSFP4_MODPRSL", "QSFP4_INTR_B", "", "", "";
                                        };
                                };

                                i2c@3 {
                                        #address-cells = <0x1>;
                                        #size-cells = <0x0>;
                                        reg = <0x3>;
                                };
                        };

                        pcie: i2c-mux@72 {
                                phandle = <0xd3>;
                                compatible = "nxp,pca9545";
                                #address-cells = <0x1>;
                                #size-cells = <0x0>;
                                #interrupt-cells = <0x2>;
                                reg = <0x72>;
                                interrupt-parent = <&gpio0>;
                                interrupts = <0xe 0x1>;
                                interrupt-controller;
                        };
                };

                ocm: memory-controller@ff960000 {
                        phandle = <0xd9>;
                        compatible = "xlnx,zynqmp-ocmc-1.0";
                        reg = <0x0 0xff960000 0x0 0x1000>;
                        interrupts = <0x0 0xa 0x4>;
                        interrupt-parent = <&imux>;
                };

                sdhci0: mmc@f1040000 {
                        phandle = <0x2d>;
                        compatible = "xlnx,versal-8.9a", "arasan,sdhci-8.9a";
                        status = "okay";
                        reg = <0x0 0xf1040000 0x0 0x10000>;
                        interrupts = <0x0 0x7e 0x4>;
                        interrupt-parent = <&imux>;
                        clock-names = "clk_xin", "clk_ahb", "gate";
                        #clock-cells = <0x1>;
                        clock-output-names = "clk_out_sd0", "clk_in_sd0";
                        clocks = <&versal_clk 0x3b>,
                         <&versal_clk 0x52>,
                         <&versal_clk 0x4a>;
                        power-domains = <&versal_firmware 0x1822402e>;
                        xlnx,sd-board-interface = "custom";
                        xlnx,is-cache-coherent = <0x0>;
                        xlnx,clk-50-ddr-otap-dly = <0x5>;
                        xlnx,clk-50-sdr-itap-dly = <0x16>;
                        xlnx,has-emio = <0x0>;
                        clock-frequency = <0xbebc149>;
                        xlnx,clk-100-sdr-otap-dly = <0x0>;
                        xlnx,mio-bank = <0x0>;
                        xlnx,ip-name = "psv_pmc_sd";
                        xlnx,bus-width = <0x8>;
                        xlnx,card-detect = <0x0>;
                        xlnx,has-wp = <0x0>;
                        xlnx,has-cd = <0x0>;
                        xlnx,slot-type = <0x1>;
                        xlnx,clk-50-sdr-otap-dly = <0x5>;
                        xlnx,clk-50-ddr-itap-dly = <0x1e>;
                        xlnx,has-power = <0x0>;
                        xlnx,clk-200-sdr-otap-dly = <0x2>;
                        xlnx,sdio-clk-freq-hz = <0xbebc149>;
                        xlnx,write-protect = <0x0>;
                        xlnx,name = "versal_cips_0_pspmc_0_psv_pmc_sd_0";
                        non-removable;
                        disable-wp;
                        no-sd;
                        no-sdio;
                        no-1-8-v;
                        cap-mmc-hw-reset;
                        bus-width = <0x8>;
                        clk-phase-mmc-hs = <0x42 0x3c>;
                };

                serial0: serial@ff000000 {
                        phandle = <0x63>;
                        compatible = "arm,pl011", "arm,primecell";
                        status = "okay";
                        reg = <0x0 0xff000000 0x0 0x1000>;
                        interrupts = <0x0 0x12 0x4>;
                        interrupt-parent = <&imux>;
                        reg-io-width = <0x4>;
                        clock-names = "uartclk", "apb_pclk";
                        bootph-all;
                        clocks = <&versal_clk 0x5c>,
                         <&versal_clk 0x52>;
                        power-domains = <&versal_firmware 0x18224021>;
                        xlnx,clock-freq = <0x5f5e0a4>;
                        u-boot,dm-pre-reloc;
                        xlnx,uart-board-interface = "custom";
                        xlnx,has-modem = <0x0>;
                        xlnx,ip-name = "psv_sbsauart";
                        xlnx,baudrate = <0x1c200>;
                        cts-override;
                        port-number = <0x0>;
                        xlnx,uart-clk-freq-hz = <0x5f5e0a4>;
                        xlnx,name = "versal_cips_0_pspmc_0_psv_sbsauart_0";
                };

                serial1: serial@ff010000 {
                        phandle = <0x64>;
                        compatible = "arm,pl011", "arm,primecell";
                        status = "okay";
                        reg = <0x0 0xff010000 0x0 0x1000>;
                        interrupts = <0x0 0x13 0x4>;
                        interrupt-parent = <&imux>;
                        reg-io-width = <0x4>;
                        clock-names = "uartclk", "apb_pclk";
                        bootph-all;
                        clocks = <&versal_clk 0x5d>,
                         <&versal_clk 0x52>;
                        power-domains = <&versal_firmware 0x18224022>;
                        xlnx,clock-freq = <0x5f5e0a4>;
                        u-boot,dm-pre-reloc;
                        xlnx,uart-board-interface = "custom";
                        xlnx,has-modem = <0x0>;
                        xlnx,ip-name = "psv_sbsauart";
                        xlnx,baudrate = <0x1c200>;
                        cts-override;
                        port-number = <0x0>;
                        xlnx,uart-clk-freq-hz = <0x5f5e0a4>;
                        xlnx,name = "versal_cips_0_pspmc_0_psv_sbsauart_1";
                };

                ospi: spi@f1010000 {
                        phandle = <0x2b>;
                        compatible = "xlnx,versal-ospi-1.0", "cdns,qspi-nor";
                        status = "okay";
                        reg = <0x0 0xf1010000 0x0 0x10000 0x0 0xc0000000 0x0 0x20000000>;
                        interrupts = <0x0 0x7c 0x4>;
                        interrupt-parent = <&imux>;
                        cdns,fifo-depth = <0x100>;
                        cdns,fifo-width = <0x4>;
                        cdns,is-dma = <0x1>;
                        cdns,trigger-address = <0xc0000000>;
                        #address-cells = <0x1>;
                        #size-cells = <0x0>;
                        clocks = <&versal_clk 0x3a>;
                        power-domains = <&versal_firmware 0x1822402a>;
                        reset-names = "qspi";
                        resets = <&versal_reset 0xc10402e>;
                        is-stacked = <0x0>;
                        xlnx,is-cache-coherent = <0x0>;
                        xlnx,clock-freq = <0xbebc149>;
                        xlnx,ip-name = "psv_pmc_ospi";
                        xlnx,ospi-clk-freq-hz = <0xbebc149>;
                        is-dual = <0x0>;
                        xlnx,ospi-mode = <0x0>;
                        xlnx,name = "versal_cips_0_pspmc_0_psv_pmc_ospi_0";
                        bus-num = <0x2>;
                        num-cs = <0x1>;

                        ospi_flash: flash@0 {
                                phandle = <0xdb>;
                                compatible = "jedec,spi-nor";
                                reg = <0x0>;
                                #address-cells = <0x1>;
                                #size-cells = <0x1>;
                                cdns,read-delay = <0x0>;
                                cdns,tshsl-ns = <0x0>;
                                cdns,tsd2d-ns = <0x0>;
                                cdns,tchsh-ns = <0x1>;
                                cdns,tslch-ns = <0x1>;
                                spi-tx-bus-width = <0x8>;
                                spi-rx-bus-width = <0x8>;
                                spi-max-frequency = <0x1312d00>;
                                no-wp;
                                reset-gpios = <&gpio1 0xc 0x1>;

                                partition@0 {
                                        label = "spi0-flash0";
                                        reg = <0x0 0x8000000>;
                                };
                        };
                };

                spi0: spi@ff040000 {
                        phandle = <0x67>;
                        compatible = "cdns,spi-r1p6";
                        status = "okay";
                        reg = <0x0 0xff040000 0x0 0x1000>;
                        interrupts = <0x0 0x10 0x4>;
                        interrupt-parent = <&imux>;
                        clock-names = "ref_clk", "pclk";
                        #address-cells = <0x1>;
                        #size-cells = <0x0>;
                        clocks = <&versal_clk 0x5e>,
                         <&versal_clk 0x52>;
                        power-domains = <&versal_firmware 0x1822401b>;
                        xlnx,spi-board-interface = "custom";
                        xlnx,has-ss0 = <0x1>;
                        xlnx,ip-name = "psv_spi";
                        xlnx,has-ss1 = <0x0>;
                        num-cs = <0x1>;
                        xlnx,spi-clk-freq-hz = <0xbebc149>;
                        xlnx,has-ss2 = <0x0>;
                        xlnx,name = "versal_cips_0_pspmc_0_psv_spi_0";

                        flash@0 {
                                compatible = "jedec,spi-nor";
                                spi-max-frequency = <0x7ed6b40>;
                                reg = <0x0>;
                        };
                };

                sysmon0: sysmon@f1270000 {
                        phandle = <0x3d>;
                        compatible = "xlnx,versal-sysmon";
                        #io-channel-cells = <0x1>;
                        reg = <0x0 0xf1270000 0x0 0x4000>;
                        interrupts = <0x0 0x90 0x4>;
                        xlnx,numchannels = [00];
                        #address-cells = <0x2>;
                        #size-cells = <0x2>;
                        xlnx,nodeid = <0x18224055>;
                        xlnx,sat-63-desc = "PS , FPD , satellite";
                        xlnx,sat-17-x = <0x35e5>;
                        xlnx,sat-1-desc = "PMC , system , ADC";
                        xlnx,sat-9-x = <0x6ed4>;
                        xlnx,sat-17-y = <0x676f>;
                        xlnx,sat-19-desc = "VNOC , satellite";
                        xlnx,sat-20-desc = "HBM , Satellite , (right)";
                        xlnx,sat-9-y = <0x772d>;
                        xlnx,sat-22-x = <0x21a7>;
                        xlnx,ip-name = "psv_pmc_sysmon";
                        xlnx,sat-22-y = <0x7362>;
                        xlnx,sat-16-desc = "HBM , Satellite , (left)";
                        xlnx,sat-9-desc = "Clocking , column , satellite";
                        xlnx,sat-26-x = <0xf56>;
                        xlnx,sat-28-desc = "Clocking , column , satellite";
                        xlnx,sat-26-y = <0x7cf2>;
                        xlnx,sat-10-x = <0x6ed4>;
                        xlnx,sat-64-x = <0x56b>;
                        xlnx,sat-2-x = <0x56b>;
                        xlnx,sat-10-y = <0x70fe>;
                        xlnx,sat-64-y = <0xf11>;
                        xlnx,sat-2-y = <0x649d>;
                        xlnx,sat-13-desc = "VNOC , satellite";
                        xlnx,sat-6-desc = "HBM , Satellite , (right)";
                        xlnx,sat-14-x = <0x4a23>;
                        xlnx,sat-6-x = <0x5f7a>;
                        xlnx,sat-25-desc = "Clocking , column , satellite";
                        xlnx,sat-14-y = <0x7362>;
                        xlnx,sat-6-y = <0x9780>;
                        xlnx,sat-10-desc = "Clocking , column , satellite";
                        xlnx,sat-18-x = <0x35e5>;
                        xlnx,sat-3-desc = "VNOC , satellite";
                        xlnx,sat-18-y = <0x7362>;
                        xlnx,sat-22-desc = "VNOC , satellite";
                        xlnx,sat-23-x = <0x21a7>;
                        xlnx,sat-23-y = <0x7f56>;
                        xlnx,sat-18-desc = "VNOC , satellite";
                        xlnx,sat-27-x = <0xf56>;
                        xlnx,sat-27-y = <0x772d>;
                        xlnx,sat-11-x = <0x6ed4>;
                        xlnx,sat-3-x = <0x5e61>;
                        xlnx,sat-11-y = <0x6b39>;
                        xlnx,sat-3-y = <0x676f>;
                        status = "okay";
                        xlnx,sat-15-desc = "VNOC , satellite";
                        xlnx,sat-15-x = <0x4a23>;
                        xlnx,sat-8-desc = "Clocking , column , satellite";
                        xlnx,sat-7-x = <0x6ed4>;
                        xlnx,name = "versal_cips_0_pspmc_0_psv_pmc_sysmon_0";
                        xlnx,sat-15-y = <0x7f56>;
                        xlnx,sat-7-y = <0x8321>;
                        xlnx,sat-27-desc = "Clocking , column , satellite";
                        xlnx,sat-12-desc = "Clocking , column , satellite";
                        xlnx,sat-19-x = <0x35e5>;
                        xlnx,sat-20-x = <0x3441>;
                        xlnx,sat-19-y = <0x7f56>;
                        xlnx,sat-20-y = <0x9780>;
                        xlnx,sat-5-desc = "VNOC , satellite";
                        xlnx,sat-24-desc = "HBM , Satellite , (left)";
                        xlnx,sat-24-x = <0x1ea8>;
                        xlnx,sat-24-y = <0x9780>;
                        xlnx,sat-64-desc = "PS , LPD , satellite";
                        xlnx,sat-2-desc = "PMC , user , ADC";
                        xlnx,sat-28-x = <0xf56>;
                        xlnx,sat-21-desc = "VNOC , satellite";
                        xlnx,sat-28-y = <0x70fe>;
                        xlnx,sat-12-x = <0x6ed4>;
                        xlnx,sat-4-x = <0x5e61>;
                        xlnx,sat-12-y = <0x650b>;
                        xlnx,sat-4-y = <0x7362>;
                        xlnx,sat-16-x = <0x49e0>;
                        xlnx,sat-17-desc = "VNOC , satellite";
                        xlnx,sat-8-x = <0x6ed4>;
                        xlnx,sat-16-y = <0x9780>;
                        xlnx,sat-8-y = <0x7cf2>;
                        xlnx,sat-21-x = <0x21a7>;
                        xlnx,sat-14-desc = "VNOC , satellite";
                        xlnx,sat-21-y = <0x676f>;
                        xlnx,sat-7-desc = "Clocking , column , satellite";
                        xlnx,sat-26-desc = "Clocking , column , satellite";
                        xlnx,sat-25-x = <0xf56>;
                        xlnx,sat-25-y = <0x8321>;
                        xlnx,sat-63-x = <0x56b>;
                        xlnx,sat-11-desc = "Clocking , column , satellite";
                        xlnx,sat-1-x = <0x56b>;
                        xlnx,sat-63-y = <0xf11>;
                        xlnx,sat-1-y = <0x649d>;
                        xlnx,sat-4-desc = "VNOC , satellite";
                        xlnx,sat-13-x = <0x4a23>;
                        xlnx,sat-23-desc = "VNOC , satellite";
                        xlnx,sat-5-x = <0x5e61>;
                        xlnx,sat-13-y = <0x676f>;
                        xlnx,sat-5-y = <0x7f56>;
                };

                ttc0: timer@ff0e0000 {
                        phandle = <0x6b>;
                        compatible = "cdns,ttc";
                        status = "okay";
                        interrupts = <0x0 0x25 0x4 0x0 0x26 0x4 0x0 0x27 0x4>;
                        interrupt-parent = <&imux>;
                        reg = <0x0 0xff0e0000 0x0 0x1000>;
                        timer-width = <0x20>;
                        clocks = <&versal_clk 0x27>;
                        power-domains = <&versal_firmware 0x18224024>;
                        xlnx,ttc-board-interface = "custom";
                        xlnx,ttc-clk2-freq-hz = <0x8f0d0f7>;
                        xlnx,ttc-clk1-clksrc = <0x0>;
                        xlnx,clock-freq = <0x8f0d0f7>;
                        xlnx,ttc-clk2-clksrc = <0x0>;
                        xlnx,ip-name = "psv_ttc";
                        xlnx,ttc-clk0-freq-hz = <0x8f0d0f7>;
                        xlnx,ttc-clk1-freq-hz = <0x8f0d0f7>;
                        xlnx,ttc-clk0-clksrc = <0x0>;
                        xlnx,name = "versal_cips_0_pspmc_0_psv_ttc_0";
                };

                ttc1: timer@ff0f0000 {
                        phandle = <0x6c>;
                        compatible = "cdns,ttc";
                        status = "okay";
                        interrupts = <0x0 0x28 0x4 0x0 0x29 0x4 0x0 0x2a 0x4>;
                        interrupt-parent = <&imux>;
                        reg = <0x0 0xff0f0000 0x0 0x1000>;
                        timer-width = <0x20>;
                        clocks = <&versal_clk 0x28>;
                        power-domains = <&versal_firmware 0x18224025>;
                        xlnx,ttc-board-interface = "custom";
                        xlnx,ttc-clk2-freq-hz = <0x8f0d0f7>;
                        xlnx,ttc-clk1-clksrc = <0x0>;
                        xlnx,clock-freq = <0x8f0d0f7>;
                        xlnx,ttc-clk2-clksrc = <0x0>;
                        xlnx,ip-name = "psv_ttc";
                        xlnx,ttc-clk0-freq-hz = <0x8f0d0f7>;
                        xlnx,ttc-clk1-freq-hz = <0x8f0d0f7>;
                        xlnx,ttc-clk0-clksrc = <0x0>;
                        xlnx,name = "versal_cips_0_pspmc_0_psv_ttc_1";
                };

                ttc2: timer@ff100000 {
                        phandle = <0x6d>;
                        compatible = "cdns,ttc";
                        status = "okay";
                        interrupts = <0x0 0x2b 0x4 0x0 0x2c 0x4 0x0 0x2d 0x4>;
                        interrupt-parent = <&imux>;
                        reg = <0x0 0xff100000 0x0 0x1000>;
                        timer-width = <0x20>;
                        clocks = <&versal_clk 0x29>;
                        power-domains = <&versal_firmware 0x18224026>;
                        xlnx,ttc-board-interface = "custom";
                        xlnx,ttc-clk2-freq-hz = <0x8f0d0f7>;
                        xlnx,ttc-clk1-clksrc = <0x0>;
                        xlnx,clock-freq = <0x8f0d0f7>;
                        xlnx,ttc-clk2-clksrc = <0x0>;
                        xlnx,ip-name = "psv_ttc";
                        xlnx,ttc-clk0-freq-hz = <0x8f0d0f7>;
                        xlnx,ttc-clk1-freq-hz = <0x8f0d0f7>;
                        xlnx,ttc-clk0-clksrc = <0x0>;
                        xlnx,name = "versal_cips_0_pspmc_0_psv_ttc_2";
                };

                ttc3: timer@ff110000 {
                        phandle = <0x6e>;
                        compatible = "cdns,ttc";
                        status = "okay";
                        interrupts = <0x0 0x2e 0x4 0x0 0x2f 0x4 0x0 0x30 0x4>;
                        interrupt-parent = <&imux>;
                        reg = <0x0 0xff110000 0x0 0x1000>;
                        timer-width = <0x20>;
                        clocks = <&versal_clk 0x2a>;
                        power-domains = <&versal_firmware 0x18224027>;
                        xlnx,ttc-board-interface = "custom";
                        xlnx,ttc-clk2-freq-hz = <0x8f0d0f7>;
                        xlnx,ttc-clk1-clksrc = <0x0>;
                        xlnx,clock-freq = <0x8f0d0f7>;
                        xlnx,ttc-clk2-clksrc = <0x0>;
                        xlnx,ip-name = "psv_ttc";
                        xlnx,ttc-clk0-freq-hz = <0x8f0d0f7>;
                        xlnx,ttc-clk1-freq-hz = <0x8f0d0f7>;
                        xlnx,ttc-clk0-clksrc = <0x0>;
                        xlnx,name = "versal_cips_0_pspmc_0_psv_ttc_3";
                };

                dma0: pmcdma@f11c0000 {
                        phandle = <0x32>;
                        status = "okay";
                        compatible = "xlnx,zynqmp-csudma-1.0";
                        interrupt-parent = <&imux>;
                        interrupts = <0x0 0x83 0x4>;
                        reg = <0x0 0xf11c0000 0x0 0x10000>;
                        xlnx,dma-type = <0x1>;
                        xlnx,ip-name = "psv_pmc_dma";
                        xlnx,name = "versal_cips_0_pspmc_0_psv_pmc_dma_0";
                };

                dma1: pmcdma@f11d0000 {
                        phandle = <0x33>;
                        status = "okay";
                        compatible = "xlnx,zynqmp-csudma-1.0";
                        interrupt-parent = <&imux>;
                        interrupts = <0x0 0x84 0x4>;
                        reg = <0x0 0xf11d0000 0x0 0x10000>;
                        xlnx,dma-type = <0x2>;
                        xlnx,ip-name = "psv_pmc_dma";
                        xlnx,name = "versal_cips_0_pspmc_0_psv_pmc_dma_1";
                };

                pmc_trng: pmc_trng@f1230000 {
                        phandle = <0x39>;
                        compatible = "xlnx,psv-pmc-trng-1.0";
                        status = "okay";
                        reg = <0x0 0xf1230000 0x0 0x10000>;
                        xlnx,device-id = <0x0>;
                        xlnx,ip-name = "psv_pmc_trng";
                        xlnx,name = "versal_cips_0_pspmc_0_psv_pmc_trng";
                };

                pmc_cfi_cframe_0: cframe@f12d0000 {
                        phandle = <0x40>;
                        compatible = "xlnx,psv-pmc-cfi-cframe-1.0";
                        status = "okay";
                        reg = <0x0 0xf12d0000 0x0 0x1000>;
                        xlnx,ip-name = "psv_pmc_cfi_cframe";
                        xlnx,name = "versal_cips_0_pspmc_0_psv_pmc_cfi_cframe_0";
                };

                pmc_cfu_apb_0: cfu_apb@f12b0000 {
                        phandle = <0x3f>;
                        compatible = "xlnx,psv-pmc-cfu-apb-1.0";
                        status = "okay";
                        reg = <0x0 0xf12b0000 0x0 0x10000>;
                        xlnx,ip-name = "psv_pmc_cfu_apb";
                        xlnx,name = "versal_cips_0_pspmc_0_psv_pmc_cfu_apb_0";
                };

                pmc_ppu1_mdm_0: ppu1_mdm@f0310000 {
                        phandle = <0xa>;
                        compatible = "xlnx,psv-pmc-ppu1-mdm-1.0";
                        status = "okay";
                        reg = <0x0 0xf0310000 0x0 0x8000>;
                        xlnx,ip-name = "psv_pmc_ppu1_mdm";
                        xlnx,name = "versal_cips_0_pspmc_0_psv_pmc_ppu1_mdm_0";
                };

                iomodule0: iomodule@f0280000 {
                        phandle = <0x8c>;
                        status = "okay";
                        compatible = "xlnx,iomodule-3.1";
                        reg = <0x0 0xf0280000 0x0 0x1000 0xffffffff 0xffffffff 0x0 0xe0000>;
                        xlnx,intc-has-fast = <0x0>;
                        xlnx,intc-base-vectors = <0xf0240000>;
                        xlnx,intc-addr-width = <0x20>;
                        xlnx,intc-level-edge = <0x7fff>;
                        xlnx,clock-freq = <0x5f5e100>;
                        xlnx,uart-baudrate = <0x1c200>;
                        xlnx,pit-used = <0x1 0x1 0x1 0x1>;
                        xlnx,pit-size = <0x20 0x20 0x20 0x20>;
                        xlnx,pit-mask = <0xffffffff 0xffffffff 0xffffffff 0xffffffff>;
                        xlnx,pit-prescaler = <0x9 0x0 0x9 0x0>;
                        xlnx,pit-readable = <0x1 0x1 0x1 0x1>;
                        xlnx,gpo-init = <0x0 0x0 0x0 0x0>;
                        xlnx,options = <0x1>;
                        xlnx,max-intr-size = <0x20>;
                        xlnx,gpo4-size = <0x20>;
                        xlnx,tmr = <0x0>;
                        xlnx,pit1-readable = <0x1>;
                        xlnx,mask = <0xfffff000>;
                        xlnx,pit2-prescaler = <0x0>;
                        xlnx,gpi3-interrupt = <0x0>;
                        xlnx,intc-positive = <0xffff>;
                        xlnx,ip-name = "iomodule";
                        xlnx,gpo1-size = <0x3>;
                        xlnx,pit3-size = <0x20>;
                        xlnx,fit3-interrupt = <0x0>;
                        xlnx,fit1-no-clocks = <0x1848>;
                        xlnx,gpi2-size = <0x20>;
                        xlnx,pit2-readable = <0x1>;
                        xlnx,intc-irq-connection = <0x0>;
                        xlnx,uart-tx-interrupt = <0x1>;
                        xlnx,use-config-reset = <0x0>;
                        xlnx,pit2-interrupt = <0x1>;
                        xlnx,gpo4-init = <0x0>;
                        xlnx,pit3-readable = <0x1>;
                        xlnx,pit3-prescaler = <0x9>;
                        xlnx,gpi4-interrupt = <0x0>;
                        xlnx,gpo1-init = <0x0>;
                        xlnx,use-io-bus = <0x0>;
                        xlnx,use-gpo1 = <0x1>;
                        xlnx,fit4-interrupt = <0x0>;
                        xlnx,gpo3-size = <0x20>;
                        xlnx,use-gpo2 = <0x0>;
                        xlnx,uart-data-bits = <0x8>;
                        xlnx,gpio1-board-interface = "Custom";
                        xlnx,use-gpo3 = <0x0>;
                        xlnx,fit2-no-clocks = <0x1848>;
                        xlnx,gpio2-board-interface = "Custom";
                        xlnx,use-gpo4 = <0x0>;
                        xlnx,gpi4-size = <0x20>;
                        xlnx,gpio3-board-interface = "Custom";
                        xlnx,uart-rx-interrupt = <0x1>;
                        xlnx,uart-error-interrupt = <0x1>;
                        xlnx,gpio4-board-interface = "Custom";
                        xlnx,pit4-readable = <0x1>;
                        xlnx,intc-use-irq-out = <0x0>;
                        xlnx,use-board-flow;
                        xlnx,pit2-size = <0x20>;
                        xlnx,intc-intr-size = <0x10>;
                        xlnx,intc-use-ext-intr = <0x1>;
                        xlnx,name = "versal_cips_0_pspmc_0_psv_pmc_iomodule_0";
                        xlnx,gpi1-size = <0x20>;
                        xlnx,edk-special = "INTR_CTRL";
                        xlnx,pit3-interrupt = <0x1>;
                        xlnx,use-gpi1 = <0x0>;
                        xlnx,gpi1-interrupt = <0x0>;
                        xlnx,use-gpi2 = <0x0>;
                        xlnx,use-gpi3 = <0x0>;
                        xlnx,use-gpi4 = <0x0>;
                        xlnx,fit1-interrupt = <0x0>;
                        xlnx,pit4-prescaler = <0x0>;
                        xlnx,gpo3-init = <0x0>;
                        xlnx,edk-iptype = "PERIPHERAL";
                        xlnx,fit3-no-clocks = <0x1848>;
                        xlnx,use-uart-rx = <0x1>;
                        xlnx,instance = "iomodule_0";
                        xlnx,uart-prog-baudrate = <0x1>;
                        xlnx,use-pit1 = <0x1>;
                        xlnx,gpo2-size = <0x20>;
                        xlnx,use-pit2 = <0x1>;
                        xlnx,pit4-size = <0x20>;
                        xlnx,use-pit3 = <0x1>;
                        xlnx,use-pit4 = <0x1>;
                        xlnx,pit4-interrupt = <0x1>;
                        xlnx,gpi3-size = <0x20>;
                        xlnx,intc-async-intr = <0xffff>;
                        xlnx,avoid-primitives = <0x0>;
                        xlnx,gpi2-interrupt = <0x0>;
                        xlnx,pit1-prescaler = <0x9>;
                        xlnx,use-tmr-disable = <0x0>;
                        xlnx,use-fit1 = <0x0>;
                        xlnx,pit1-size = <0x20>;
                        xlnx,intc-num-sync-ff = <0x2>;
                        xlnx,uart-board-interface = "rs232_uart";
                        xlnx,use-fit2 = <0x0>;
                        xlnx,fit2-interrupt = <0x0>;
                        xlnx,use-fit3 = <0x0>;
                        xlnx,use-fit4 = <0x0>;
                        xlnx,io-baseaddr = <0xffffffff 0xffffffff>;
                        xlnx,uart-use-parity = <0x0>;
                        xlnx,lmb-dwidth = <0x20>;
                        xlnx,fit4-no-clocks = <0x1848>;
                        xlnx,uart-odd-parity = <0x0>;
                        xlnx,freq = <0x5f5e100>;
                        xlnx,use-uart-tx = <0x1>;
                        xlnx,pit1-interrupt = <0x1>;
                        xlnx,gpo2-init = <0x0>;
                        xlnx,io-mask = <0xfffe0000>;
                        xlnx,lmb-awidth = <0x20>;
                };

                ipi_pmc: mailbox@ff320000 {
                        phandle = <0x8a>;
                        status = "okay";
                        compatible = "xlnx,versal-ipi-mailbox";
                        interrupt-parent = <&imux>;
                        interrupts = <0x0 0x1b 0x4>;
                        reg = <0x0 0xff320000 0x0 0x10000 0x0 0xff3f0200 0x0 0x200>;
                        xlnx,ipi-bitmask = <0x2>;
                        xlnx,ipi-id = <0x1>;
                        xlnx,ipi-buf-index = <0x1>;
                        #address-cells = <0x2>;
                        #size-cells = <0x2>;
                        ranges;
                        xlnx,cpu-name = "PMC";
                        xlnx,buffer-base = <0xff3f0200>;
                        xlnx,buffer-index = <0x1>;
                        xlnx,ip-name = "psv_ipi";
                        xlnx,ipi-target-count = <0xa>;
                        reg-names = "ctrl", "msg";
                        xlnx,int-id = <0x3b>;
                        xlnx,bit-position = <0x1>;
                        xlnx,name = "versal_cips_0_pspmc_0_psv_ipi_pmc";

                        ipi_pmc_to_ipi_0: child@ff330000 {
                                phandle = <0xe8>;
                                compatible = "xlnx,versal-ipi-dest-mailbox";
                                xlnx,ipi-bitmask = <0x4>;
                                xlnx,cpu-name = "A72";
                                xlnx,ipi-rsp-msg-buf = <0xff3f02a0>;
                                #mbox-cells = <0x1>;
                                xlnx,ipi-id = <0x2>;
                                reg = <0x0 0xff330000 0x0 0x10000 0x0 0xff3f0400 0x0 0x200>;
                                xlnx,ipi-buf-index = <0x2>;
                                xlnx,ipi-req-msg-buf = <0xff3f0280>;
                                reg-names = "ctrl", "msg";
                        };

                        ipi_pmc_to_ipi_1: child@ff340000 {
                                phandle = <0xe9>;
                                compatible = "xlnx,versal-ipi-dest-mailbox";
                                xlnx,ipi-bitmask = <0x8>;
                                xlnx,cpu-name = "A72";
                                xlnx,ipi-rsp-msg-buf = <0xff3f02e0>;
                                #mbox-cells = <0x1>;
                                xlnx,ipi-id = <0x3>;
                                reg = <0x0 0xff340000 0x0 0x10000 0x0 0xff3f0600 0x0 0x200>;
                                xlnx,ipi-buf-index = <0x3>;
                                xlnx,ipi-req-msg-buf = <0xff3f02c0>;
                                reg-names = "ctrl", "msg";
                        };

                        ipi_pmc_to_ipi_2: child@ff350000 {
                                phandle = <0xea>;
                                compatible = "xlnx,versal-ipi-dest-mailbox";
                                xlnx,ipi-bitmask = <0x10>;
                                xlnx,cpu-name = "A72";
                                xlnx,ipi-rsp-msg-buf = <0xff3f0320>;
                                #mbox-cells = <0x1>;
                                xlnx,ipi-id = <0x4>;
                                reg = <0x0 0xff350000 0x0 0x10000 0x0 0xff3f0800 0x0 0x200>;
                                xlnx,ipi-buf-index = <0x4>;
                                xlnx,ipi-req-msg-buf = <0xff3f0300>;
                                reg-names = "ctrl", "msg";
                        };

                        ipi_pmc_to_ipi_3: child@ff360000 {
                                phandle = <0xeb>;
                                compatible = "xlnx,versal-ipi-dest-mailbox";
                                xlnx,ipi-bitmask = <0x20>;
                                xlnx,cpu-name = "R5_0";
                                xlnx,ipi-rsp-msg-buf = <0xff3f0360>;
                                #mbox-cells = <0x1>;
                                xlnx,ipi-id = <0x5>;
                                reg = <0x0 0xff360000 0x0 0x10000 0x0 0xff3f0a00 0x0 0x200>;
                                xlnx,ipi-buf-index = <0x5>;
                                xlnx,ipi-req-msg-buf = <0xff3f0340>;
                                reg-names = "ctrl", "msg";
                        };

                        ipi_pmc_to_ipi_4: child@ff370000 {
                                phandle = <0xec>;
                                compatible = "xlnx,versal-ipi-dest-mailbox";
                                xlnx,ipi-bitmask = <0x40>;
                                xlnx,cpu-name = "R5_0";
                                xlnx,ipi-rsp-msg-buf = <0xff3f03a0>;
                                #mbox-cells = <0x1>;
                                xlnx,ipi-id = <0x6>;
                                reg = <0x0 0xff370000 0x0 0x10000 0x0 0xff3f0c00 0x0 0x200>;
                                xlnx,ipi-buf-index = <0x6>;
                                xlnx,ipi-req-msg-buf = <0xff3f0380>;
                                reg-names = "ctrl", "msg";
                        };

                        ipi_pmc_to_ipi_5: child@ff380000 {
                                phandle = <0xed>;
                                compatible = "xlnx,versal-ipi-dest-mailbox";
                                xlnx,ipi-bitmask = <0x80>;
                                xlnx,cpu-name = "R5_1";
                                xlnx,ipi-rsp-msg-buf = <0xff3f03e0>;
                                #mbox-cells = <0x1>;
                                xlnx,ipi-id = <0x7>;
                                reg = <0x0 0xff380000 0x0 0x10000 0x0 0xff3f0e00 0x0 0x200>;
                                xlnx,ipi-buf-index = <0x7>;
                                xlnx,ipi-req-msg-buf = <0xff3f03c0>;
                                reg-names = "ctrl", "msg";
                        };

                        ipi_pmc_to_ipi_6: child@ff3a0000 {
                                phandle = <0xee>;
                                compatible = "xlnx,versal-ipi-dest-mailbox";
                                xlnx,ipi-bitmask = <0x200>;
                                xlnx,cpu-name = "R5_1";
                                #mbox-cells = <0x1>;
                                xlnx,ipi-id = <0x9>;
                                reg = <0x0 0xff3a0000 0x0 0x10000>;
                                xlnx,ipi-buf-index = <0xffff>;
                                reg-names = "ctrl";
                        };

                        ipi_pmc_to_ipi_pmc: child@ff320000 {
                                phandle = <0xef>;
                                compatible = "xlnx,versal-ipi-dest-mailbox";
                                xlnx,ipi-bitmask = <0x2>;
                                xlnx,cpu-name = "PMC";
                                xlnx,ipi-rsp-msg-buf = <0xff3f0260>;
                                #mbox-cells = <0x1>;
                                xlnx,ipi-id = <0x1>;
                                reg = <0x0 0xff320000 0x0 0x10000 0x0 0xff3f0200 0x0 0x200>;
                                xlnx,ipi-buf-index = <0x1>;
                                xlnx,ipi-req-msg-buf = <0xff3f0240>;
                                reg-names = "ctrl", "msg";
                        };

                        ipi_pmc_to_ipi_pmc_nobuf: child@ff390000 {
                                phandle = <0xf0>;
                                compatible = "xlnx,versal-ipi-dest-mailbox";
                                xlnx,ipi-bitmask = <0x100>;
                                xlnx,cpu-name = "PMC";
                                #mbox-cells = <0x1>;
                                xlnx,ipi-id = <0x8>;
                                reg = <0x0 0xff390000 0x0 0x10000>;
                                xlnx,ipi-buf-index = <0xffff>;
                                reg-names = "ctrl";
                        };

                        ipi_pmc_to_ipi_psm: child@ff310000 {
                                phandle = <0xf1>;
                                compatible = "xlnx,versal-ipi-dest-mailbox";
                                xlnx,ipi-bitmask = <0x1>;
                                xlnx,cpu-name = "PSM";
                                xlnx,ipi-rsp-msg-buf = <0xff3f0220>;
                                #mbox-cells = <0x1>;
                                xlnx,ipi-id = <0x0>;
                                reg = <0x0 0xff310000 0x0 0x10000 0x0 0xff3f0000 0x0 0x200>;
                                xlnx,ipi-buf-index = <0x0>;
                                xlnx,ipi-req-msg-buf = <0xff3f0200>;
                                reg-names = "ctrl", "msg";
                        };
                };

                ipi_pmc_nobuf: mailbox@ff390000 {
                        phandle = <0x8b>;
                        status = "okay";
                        compatible = "xlnx,versal-ipi-mailbox";
                        interrupt-parent = <&imux>;
                        interrupts = <0x0 0x1c 0x4>;
                        reg = <0x0 0xff390000 0x0 0x10000>;
                        xlnx,ipi-bitmask = <0x100>;
                        xlnx,ipi-id = <0x8>;
                        xlnx,ipi-buf-index = <0xffff>;
                        #address-cells = <0x2>;
                        #size-cells = <0x2>;
                        ranges;
                        xlnx,cpu-name = "PMC";
                        xlnx,buffer-base = "NIL";
                        xlnx,buffer-index = "NIL";
                        xlnx,ip-name = "psv_ipi";
                        xlnx,ipi-target-count = <0xa>;
                        reg-names = "ctrl";
                        xlnx,int-id = <0x3c>;
                        xlnx,bit-position = <0x8>;
                        xlnx,name = "versal_cips_0_pspmc_0_psv_ipi_pmc_nobuf";

                        ipi_pmc_nobuf_to_ipi_0: child@ff330000 {
                                phandle = <0xf2>;
                                compatible = "xlnx,versal-ipi-dest-mailbox";
                                xlnx,ipi-bitmask = <0x4>;
                                xlnx,cpu-name = "A72";
                                #mbox-cells = <0x1>;
                                xlnx,ipi-id = <0x2>;
                                reg = <0x0 0xff330000 0x0 0x10000 0x0 0xff3f0400 0x0 0x200>;
                                xlnx,ipi-buf-index = <0x2>;
                                reg-names = "ctrl", "msg";
                        };

                        ipi_pmc_nobuf_to_ipi_1: child@ff340000 {
                                phandle = <0xf3>;
                                compatible = "xlnx,versal-ipi-dest-mailbox";
                                xlnx,ipi-bitmask = <0x8>;
                                xlnx,cpu-name = "A72";
                                #mbox-cells = <0x1>;
                                xlnx,ipi-id = <0x3>;
                                reg = <0x0 0xff340000 0x0 0x10000 0x0 0xff3f0600 0x0 0x200>;
                                xlnx,ipi-buf-index = <0x3>;
                                reg-names = "ctrl", "msg";
                        };

                        ipi_pmc_nobuf_to_ipi_2: child@ff350000 {
                                phandle = <0xf4>;
                                compatible = "xlnx,versal-ipi-dest-mailbox";
                                xlnx,ipi-bitmask = <0x10>;
                                xlnx,cpu-name = "A72";
                                #mbox-cells = <0x1>;
                                xlnx,ipi-id = <0x4>;
                                reg = <0x0 0xff350000 0x0 0x10000 0x0 0xff3f0800 0x0 0x200>;
                                xlnx,ipi-buf-index = <0x4>;
                                reg-names = "ctrl", "msg";
                        };

                        ipi_pmc_nobuf_to_ipi_3: child@ff360000 {
                                phandle = <0xf5>;
                                compatible = "xlnx,versal-ipi-dest-mailbox";
                                xlnx,ipi-bitmask = <0x20>;
                                xlnx,cpu-name = "R5_0";
                                #mbox-cells = <0x1>;
                                xlnx,ipi-id = <0x5>;
                                reg = <0x0 0xff360000 0x0 0x10000 0x0 0xff3f0a00 0x0 0x200>;
                                xlnx,ipi-buf-index = <0x5>;
                                reg-names = "ctrl", "msg";
                        };

                        ipi_pmc_nobuf_to_ipi_4: child@ff370000 {
                                phandle = <0xf6>;
                                compatible = "xlnx,versal-ipi-dest-mailbox";
                                xlnx,ipi-bitmask = <0x40>;
                                xlnx,cpu-name = "R5_0";
                                #mbox-cells = <0x1>;
                                xlnx,ipi-id = <0x6>;
                                reg = <0x0 0xff370000 0x0 0x10000 0x0 0xff3f0c00 0x0 0x200>;
                                xlnx,ipi-buf-index = <0x6>;
                                reg-names = "ctrl", "msg";
                        };

                        ipi_pmc_nobuf_to_ipi_5: child@ff380000 {
                                phandle = <0xf7>;
                                compatible = "xlnx,versal-ipi-dest-mailbox";
                                xlnx,ipi-bitmask = <0x80>;
                                xlnx,cpu-name = "R5_1";
                                #mbox-cells = <0x1>;
                                xlnx,ipi-id = <0x7>;
                                reg = <0x0 0xff380000 0x0 0x10000 0x0 0xff3f0e00 0x0 0x200>;
                                xlnx,ipi-buf-index = <0x7>;
                                reg-names = "ctrl", "msg";
                        };

                        ipi_pmc_nobuf_to_ipi_6: child@ff3a0000 {
                                phandle = <0xf8>;
                                compatible = "xlnx,versal-ipi-dest-mailbox";
                                xlnx,ipi-bitmask = <0x200>;
                                xlnx,cpu-name = "R5_1";
                                #mbox-cells = <0x1>;
                                xlnx,ipi-id = <0x9>;
                                reg = <0x0 0xff3a0000 0x0 0x10000>;
                                xlnx,ipi-buf-index = <0xffff>;
                                reg-names = "ctrl";
                        };

                        ipi_pmc_nobuf_to_ipi_pmc: child@ff320000 {
                                phandle = <0xf9>;
                                compatible = "xlnx,versal-ipi-dest-mailbox";
                                xlnx,ipi-bitmask = <0x2>;
                                xlnx,cpu-name = "PMC";
                                #mbox-cells = <0x1>;
                                xlnx,ipi-id = <0x1>;
                                reg = <0x0 0xff320000 0x0 0x10000 0x0 0xff3f0200 0x0 0x200>;
                                xlnx,ipi-buf-index = <0x1>;
                                reg-names = "ctrl", "msg";
                        };

                        ipi_pmc_nobuf_to_ipi_pmc_nobuf: child@ff390000 {
                                phandle = <0xfa>;
                                compatible = "xlnx,versal-ipi-dest-mailbox";
                                xlnx,ipi-bitmask = <0x100>;
                                xlnx,cpu-name = "PMC";
                                #mbox-cells = <0x1>;
                                xlnx,ipi-id = <0x8>;
                                reg = <0x0 0xff390000 0x0 0x10000>;
                                xlnx,ipi-buf-index = <0xffff>;
                                reg-names = "ctrl";
                        };

                        ipi_pmc_nobuf_to_ipi_psm: child@ff310000 {
                                phandle = <0xfb>;
                                compatible = "xlnx,versal-ipi-dest-mailbox";
                                xlnx,ipi-bitmask = <0x1>;
                                xlnx,cpu-name = "PSM";
                                #mbox-cells = <0x1>;
                                xlnx,ipi-id = <0x0>;
                                reg = <0x0 0xff310000 0x0 0x10000 0x0 0xff3f0000 0x0 0x200>;
                                xlnx,ipi-buf-index = <0x0>;
                                reg-names = "ctrl", "msg";
                        };
                };

                versal_cips_0_pspmc_0_psv_pmc_cfi_cframe_1: versal_cips_0_pspmc_0_psv_pmc_cfi_cframe_1@f12d2000 {
                        phandle = <0x41>;
                        compatible = "xlnx,psv-pmc-cfi-cframe-1.0";
                        status = "okay";
                        xlnx,ip-name = "psv_pmc_cfi_cframe";
                        reg = <0x0 0xf12d2000 0x0 0x1000>;
                        xlnx,name = "versal_cips_0_pspmc_0_psv_pmc_cfi_cframe_1";
                };

                versal_cips_0_pspmc_0_psv_pmc_cfi_cframe_10: versal_cips_0_pspmc_0_psv_pmc_cfi_cframe_10@f12e4000 {
                        phandle = <0x4a>;
                        compatible = "xlnx,psv-pmc-cfi-cframe-1.0";
                        status = "okay";
                        xlnx,ip-name = "psv_pmc_cfi_cframe";
                        reg = <0x0 0xf12e4000 0x0 0x1000>;
                        xlnx,name = "versal_cips_0_pspmc_0_psv_pmc_cfi_cframe_10";
                };

                versal_cips_0_pspmc_0_psv_pmc_cfi_cframe_11: versal_cips_0_pspmc_0_psv_pmc_cfi_cframe_11@f12e6000 {
                        phandle = <0x4b>;
                        compatible = "xlnx,psv-pmc-cfi-cframe-1.0";
                        status = "okay";
                        xlnx,ip-name = "psv_pmc_cfi_cframe";
                        reg = <0x0 0xf12e6000 0x0 0x1000>;
                        xlnx,name = "versal_cips_0_pspmc_0_psv_pmc_cfi_cframe_11";
                };

                versal_cips_0_pspmc_0_psv_pmc_cfi_cframe_12: versal_cips_0_pspmc_0_psv_pmc_cfi_cframe_12@f12e8000 {
                        phandle = <0x4c>;
                        compatible = "xlnx,psv-pmc-cfi-cframe-1.0";
                        status = "okay";
                        xlnx,ip-name = "psv_pmc_cfi_cframe";
                        reg = <0x0 0xf12e8000 0x0 0x1000>;
                        xlnx,name = "versal_cips_0_pspmc_0_psv_pmc_cfi_cframe_12";
                };

                versal_cips_0_pspmc_0_psv_pmc_cfi_cframe_13: versal_cips_0_pspmc_0_psv_pmc_cfi_cframe_13@f12ea000 {
                        phandle = <0x4d>;
                        compatible = "xlnx,psv-pmc-cfi-cframe-1.0";
                        status = "okay";
                        xlnx,ip-name = "psv_pmc_cfi_cframe";
                        reg = <0x0 0xf12ea000 0x0 0x1000>;
                        xlnx,name = "versal_cips_0_pspmc_0_psv_pmc_cfi_cframe_13";
                };

                versal_cips_0_pspmc_0_psv_pmc_cfi_cframe_14: versal_cips_0_pspmc_0_psv_pmc_cfi_cframe_14@f12ec000 {
                        phandle = <0x4e>;
                        compatible = "xlnx,psv-pmc-cfi-cframe-1.0";
                        status = "okay";
                        xlnx,ip-name = "psv_pmc_cfi_cframe";
                        reg = <0x0 0xf12ec000 0x0 0x1000>;
                        xlnx,name = "versal_cips_0_pspmc_0_psv_pmc_cfi_cframe_14";
                };

                versal_cips_0_pspmc_0_psv_pmc_cfi_cframe_2: versal_cips_0_pspmc_0_psv_pmc_cfi_cframe_2@f12d4000 {
                        phandle = <0x42>;
                        compatible = "xlnx,psv-pmc-cfi-cframe-1.0";
                        status = "okay";
                        xlnx,ip-name = "psv_pmc_cfi_cframe";
                        reg = <0x0 0xf12d4000 0x0 0x1000>;
                        xlnx,name = "versal_cips_0_pspmc_0_psv_pmc_cfi_cframe_2";
                };

                versal_cips_0_pspmc_0_psv_pmc_cfi_cframe_3: versal_cips_0_pspmc_0_psv_pmc_cfi_cframe_3@f12d6000 {
                        phandle = <0x43>;
                        compatible = "xlnx,psv-pmc-cfi-cframe-1.0";
                        status = "okay";
                        xlnx,ip-name = "psv_pmc_cfi_cframe";
                        reg = <0x0 0xf12d6000 0x0 0x1000>;
                        xlnx,name = "versal_cips_0_pspmc_0_psv_pmc_cfi_cframe_3";
                };

                versal_cips_0_pspmc_0_psv_pmc_cfi_cframe_4: versal_cips_0_pspmc_0_psv_pmc_cfi_cframe_4@f12d8000 {
                        phandle = <0x44>;
                        compatible = "xlnx,psv-pmc-cfi-cframe-1.0";
                        status = "okay";
                        xlnx,ip-name = "psv_pmc_cfi_cframe";
                        reg = <0x0 0xf12d8000 0x0 0x1000>;
                        xlnx,name = "versal_cips_0_pspmc_0_psv_pmc_cfi_cframe_4";
                };

                versal_cips_0_pspmc_0_psv_pmc_cfi_cframe_5: versal_cips_0_pspmc_0_psv_pmc_cfi_cframe_5@f12da000 {
                        phandle = <0x45>;
                        compatible = "xlnx,psv-pmc-cfi-cframe-1.0";
                        status = "okay";
                        xlnx,ip-name = "psv_pmc_cfi_cframe";
                        reg = <0x0 0xf12da000 0x0 0x1000>;
                        xlnx,name = "versal_cips_0_pspmc_0_psv_pmc_cfi_cframe_5";
                };

                versal_cips_0_pspmc_0_psv_pmc_cfi_cframe_6: versal_cips_0_pspmc_0_psv_pmc_cfi_cframe_6@f12dc000 {
                        phandle = <0x46>;
                        compatible = "xlnx,psv-pmc-cfi-cframe-1.0";
                        status = "okay";
                        xlnx,ip-name = "psv_pmc_cfi_cframe";
                        reg = <0x0 0xf12dc000 0x0 0x1000>;
                        xlnx,name = "versal_cips_0_pspmc_0_psv_pmc_cfi_cframe_6";
                };

                versal_cips_0_pspmc_0_psv_pmc_cfi_cframe_7: versal_cips_0_pspmc_0_psv_pmc_cfi_cframe_7@f12de000 {
                        phandle = <0x47>;
                        compatible = "xlnx,psv-pmc-cfi-cframe-1.0";
                        status = "okay";
                        xlnx,ip-name = "psv_pmc_cfi_cframe";
                        reg = <0x0 0xf12de000 0x0 0x1000>;
                        xlnx,name = "versal_cips_0_pspmc_0_psv_pmc_cfi_cframe_7";
                };

                versal_cips_0_pspmc_0_psv_pmc_cfi_cframe_8: versal_cips_0_pspmc_0_psv_pmc_cfi_cframe_8@f12e0000 {
                        phandle = <0x48>;
                        compatible = "xlnx,psv-pmc-cfi-cframe-1.0";
                        status = "okay";
                        xlnx,ip-name = "psv_pmc_cfi_cframe";
                        reg = <0x0 0xf12e0000 0x0 0x1000>;
                        xlnx,name = "versal_cips_0_pspmc_0_psv_pmc_cfi_cframe_8";
                };

                versal_cips_0_pspmc_0_psv_pmc_cfi_cframe_9: versal_cips_0_pspmc_0_psv_pmc_cfi_cframe_9@f12e2000 {
                        phandle = <0x49>;
                        compatible = "xlnx,psv-pmc-cfi-cframe-1.0";
                        status = "okay";
                        xlnx,ip-name = "psv_pmc_cfi_cframe";
                        reg = <0x0 0xf12e2000 0x0 0x1000>;
                        xlnx,name = "versal_cips_0_pspmc_0_psv_pmc_cfi_cframe_9";
                };

                versal_cips_0_pspmc_0_psv_pmc_cfi_cframe_bcast: versal_cips_0_pspmc_0_psv_pmc_cfi_cframe_bcast@f12ee000 {
                        phandle = <0x4f>;
                        compatible = "xlnx,psv-pmc-cfi-cframe-1.0";
                        status = "okay";
                        xlnx,ip-name = "psv_pmc_cfi_cframe";
                        reg = <0x0 0xf12ee000 0x0 0x1000>;
                        xlnx,name = "versal_cips_0_pspmc_0_psv_pmc_cfi_cframe_bcast";
                };

                versal_cips_0_pspmc_0_psv_r5_0_atcm: versal_cips_0_pspmc_0_psv_r5_0_atcm@0 {
                        phandle = <0x96>;
                        xlnx,power-domain = <0x1831800b>;
                        compatible = "xlnx,psv-r5-tcm-1.0";
                        status = "okay";
                        xlnx,ip-name = "psv_r5_tcm";
                        xlnx,bank-size = <0x10000>;
                        reg = <0x0 0x0 0x0 0x10000>;
                        xlnx,name = "versal_cips_0_pspmc_0_psv_r5_0_atcm";
                };

                versal_cips_0_pspmc_0_psv_r5_0_atcm_lockstep: versal_cips_0_pspmc_0_psv_r5_0_atcm_lockstep@ffe10000 {
                        phandle = <0x155>;
                        compatible = "xlnx,psv-r5-0-atcm-lockstep-1.0", "mmio-sram";
                        status = "okay";
                        power-domains = <&versal_firmware 0x1831800b>;
                        xlnx,ip-name = "psv_r5_0_atcm_lockstep";
                        xlnx,is-hierarchy;
                        reg = <0x0 0xffe10000 0x0 0x10000>;
                        xlnx,name = "versal_cips_0_pspmc_0_psv_r5_0_atcm_lockstep";
                };

                versal_cips_0_pspmc_0_psv_r5_0_btcm: versal_cips_0_pspmc_0_psv_r5_0_btcm@20000 {
                        phandle = <0x98>;
                        xlnx,power-domain = <0x1831800c>;
                        compatible = "xlnx,psv-r5-tcm-1.0";
                        status = "okay";
                        xlnx,ip-name = "psv_r5_tcm";
                        xlnx,bank-size = <0x10000>;
                        reg = <0x0 0x20000 0x0 0x10000>;
                        xlnx,name = "versal_cips_0_pspmc_0_psv_r5_0_btcm";
                };

                versal_cips_0_pspmc_0_psv_r5_0_btcm_lockstep: versal_cips_0_pspmc_0_psv_r5_0_btcm_lockstep@ffe30000 {
                        phandle = <0x156>;
                        compatible = "xlnx,psv-r5-0-btcm-lockstep-1.0", "mmio-sram";
                        status = "okay";
                        power-domains = <&versal_firmware 0x1831800c>;
                        xlnx,ip-name = "psv_r5_0_btcm_lockstep";
                        xlnx,is-hierarchy;
                        reg = <0x0 0xffe30000 0x0 0x10000>;
                        xlnx,name = "versal_cips_0_pspmc_0_psv_r5_0_btcm_lockstep";
                };

                versal_cips_0_pspmc_0_psv_r5_1_atcm: versal_cips_0_pspmc_0_psv_r5_1_atcm@0 {
                        phandle = <0xa0>;
                        xlnx,power-domain = <0x1831800d>;
                        compatible = "xlnx,psv-r5-tcm-1.0";
                        status = "okay";
                        xlnx,ip-name = "psv_r5_tcm";
                        xlnx,bank-size = <0x10000>;
                        reg = <0x0 0x0 0x0 0x10000>;
                        xlnx,name = "versal_cips_0_pspmc_0_psv_r5_1_atcm";
                };

                versal_cips_0_pspmc_0_psv_r5_1_btcm: versal_cips_0_pspmc_0_psv_r5_1_btcm@20000 {
                        phandle = <0xa1>;
                        xlnx,power-domain = <0x1831800e>;
                        compatible = "xlnx,psv-r5-tcm-1.0";
                        status = "okay";
                        xlnx,ip-name = "psv_r5_tcm";
                        xlnx,bank-size = <0x10000>;
                        reg = <0x0 0x20000 0x0 0x10000>;
                        xlnx,name = "versal_cips_0_pspmc_0_psv_r5_1_btcm";
                };

                versal_cips_0_pspmc_0_psv_r5_tcm_ram_0: versal_cips_0_pspmc_0_psv_r5_tcm_ram_0@0 {
                        phandle = <0x97>;
                        compatible = "xlnx,psv-r5-tcm-1.0";
                        status = "okay";
                        xlnx,ip-name = "psv_r5_tcm";
                        reg = <0x0 0x0 0x0 0x40000>;
                        xlnx,name = "versal_cips_0_pspmc_0_psv_r5_tcm_ram_0";
                };
        };

        psv_r5_0_atcm_global: psv_r5_0_atcm_global@ffe00000 {
                phandle = <0x82>;
                compatible = "xlnx,psv-tcm-global-1.0", "mmio-sram";
                power-domains = <&versal_firmware 0x1831800b>;
                reg = <0x0 0xffe00000 0x0 0x10000>;
                status = "okay";
                xlnx,ip-name = "psv_tcm_global";
                xlnx,is-hierarchy;
                xlnx,name = "versal_cips_0_pspmc_0_psv_r5_0_atcm_global";
        };

        psv_r5_0_btcm_global: psv_r5_0_btcm_global@ffe20000 {
                phandle = <0x157>;
                compatible = "xlnx,psv-tcm-global-1.0", "mmio-sram";
                power-domains = <&versal_firmware 0x1831800c>;
                reg = <0x0 0xffe20000 0x0 0x10000>;
                status = "okay";
                xlnx,ip-name = "psv_tcm_global";
                xlnx,is-hierarchy;
                xlnx,name = "versal_cips_0_pspmc_0_psv_r5_0_btcm_global";
        };

        psv_r5_1_atcm_global: psv_r5_1_atcm_global@ffe90000 {
                phandle = <0x83>;
                compatible = "xlnx,psv-tcm-global-1.0", "mmio-sram";
                power-domains = <&versal_firmware 0x1831800d>;
                reg = <0x0 0xffe90000 0x0 0x10000>;
                status = "okay";
                xlnx,ip-name = "psv_tcm_global";
                xlnx,name = "versal_cips_0_pspmc_0_psv_r5_1_atcm_global";
        };

        psv_r5_1_btcm_global: psv_r5_1_btcm_global@ffeb0000 {
                phandle = <0x84>;
                compatible = "xlnx,psv-tcm-global-1.0", "mmio-sram";
                power-domains = <&versal_firmware 0x1831800e>;
                reg = <0x0 0xffeb0000 0x0 0x10000>;
                status = "okay";
                xlnx,ip-name = "psv_tcm_global";
                xlnx,name = "versal_cips_0_pspmc_0_psv_r5_1_btcm_global";
        };

        amba_xppu: indirect-bus@1 {
                phandle = <0x158>;
                compatible = "indirect-bus";
                #address-cells = <0x2>;
                #size-cells = <0x2>;
        };

        amba_xmpu: indirect-bus@2 {
                phandle = <0x159>;
                compatible = "indirect-bus";
                #address-cells = <0x2>;
                #size-cells = <0x2>;
        };

        pl_alt_ref: pl-alt-ref {
                phandle = <0xad>;
                bootph-all;
                compatible = "fixed-clock";
                #clock-cells = <0x0>;
                clock-frequency = <0x1fca055>;
                clock-output-names = "pl_alt_ref_clk";
        };

        ref: ref {
                phandle = <0xac>;
                bootph-all;
                compatible = "fixed-clock";
                #clock-cells = <0x0>;
                clock-frequency = <0x1fca034>;
                clock-output-names = "ref_clk";
        };

        can0_clk: can0-clk {
                phandle = <0xa5>;
                #clock-cells = <0x0>;
                compatible = "fixed-factor-clock";
                clocks = <&versal_clk 0x60>;
                clock-div = <0x2>;
                clock-mult = <0x1>;
                clock-output-names = "can0_clk";
        };

        can1_clk: can1-clk {
                phandle = <0xa6>;
                #clock-cells = <0x0>;
                compatible = "fixed-factor-clock";
                clocks = <&versal_clk 0x61>;
                clock-div = <0x2>;
                clock-mult = <0x1>;
                clock-output-names = "can1_clk";
        };

        firmware {

                versal_firmware: versal-firmware {
                        phandle = <0x87>;
                        compatible = "xlnx,versal-firmware";
                        interrupt-parent = <&imux>;
                        bootph-all;
                        method = "smc";
                        #power-domain-cells = <0x1>;

                        versal_clk: clock-controller {
                                phandle = <0x89>;
                                bootph-all;
                                #clock-cells = <0x1>;
                                compatible = "xlnx,versal-clk";
                                clocks = <&ref>,
                                 <&pl_alt_ref>;
                                clock-names = "ref", "pl_alt_ref";
                        };

                        zynqmp_power: power-management {
                                phandle = <0x15e>;
                                compatible = "xlnx,zynqmp-power";
                        };

                        versal_reset: reset-controller {
                                phandle = <0xa9>;
                                compatible = "xlnx,versal-reset";
                                #reset-cells = <0x1>;
                        };

                        pinctrl0: pinctrl {
                                phandle = <0x15f>;
                                compatible = "xlnx,versal-pinctrl";
                        };

                        versal_sec_cfg: versal-sec-cfg {
                                phandle = <0x160>;
                                compatible = "xlnx,versal-sec-cfg";

                                nvmem-layout {
                                        compatible = "fixed-layout";
                                        #address-cells = <0x1>;
                                        #size-cells = <0x1>;

                                        bbram_zeroize: bbram-zeroize@4 {
                                                phandle = <0x161>;
                                                reg = <0x4 0x4>;
                                        };

                                        bbram_key: bbram-key@10 {
                                                phandle = <0x162>;
                                                reg = <0x10 0x20>;
                                        };

                                        bbram_usr: bbram-usr@30 {
                                                phandle = <0x163>;
                                                reg = <0x30 0x4>;
                                        };

                                        bbram_lock: bbram-lock@48 {
                                                phandle = <0x164>;
                                                reg = <0x48 0x4>;
                                        };

                                        user_key0: user-key@110 {
                                                phandle = <0x165>;
                                                reg = <0x110 0x20>;
                                        };

                                        user_key1: user-key@130 {
                                                phandle = <0x166>;
                                                reg = <0x130 0x20>;
                                        };

                                        user_key2: user-key@150 {
                                                phandle = <0x167>;
                                                reg = <0x150 0x20>;
                                        };

                                        user_key3: user-key@170 {
                                                phandle = <0x168>;
                                                reg = <0x170 0x20>;
                                        };

                                        user_key4: user-key@190 {
                                                phandle = <0x169>;
                                                reg = <0x190 0x20>;
                                        };

                                        user_key5: user-key@1b0 {
                                                phandle = <0x16a>;
                                                reg = <0x1b0 0x20>;
                                        };

                                        user_key6: user-key@1d0 {
                                                phandle = <0x16b>;
                                                reg = <0x1d0 0x20>;
                                        };

                                        user_key7: user-key@1f0 {
                                                phandle = <0x16c>;
                                                reg = <0x1f0 0x20>;
                                        };
                                };
                        };
                };
        };

        amba_pl: amba_pl {
                phandle = <0x16d>;
                ranges;
                compatible = "simple-bus";
                #address-cells = <0x2>;
                #size-cells = <0x2>;
                firmware-name = "v80_base_pld.pdi";
        };

        chosen {
                stdout-path = "serial0:115200n8";
        };

        aliases {
                serial0 = "/axi/serial@ff000000";
                serial1 = "/axi/serial@ff010000";
                serial2 = "/axi/coresight@f0800000";
                i2c0 = "/axi/i2c@ff020000";
                i2c1 = "/axi/i2c@ff030000";
                mmc0 = "/axi/mmc@f1040000";
                spi0 = "/axi/spi@f1010000";
                rtc0 = "/axi/rtc@f12a0000";
        };

        __symbols__ {
                l2 = "/l2-cache";
                cpus_microblaze_0 = "/cpus_microblaze@0";
                psv_pmc_0 = "/cpus_microblaze@0/cpu@0";
                cpu_opp_table = "/opp-table-cpu";
                fpga = "/fpga-region";
                psci = "/psci";
                timer = "/timer";
                versal_fpga = "/versal-fpga";
                sensor0 = "/versal-thermal-sensor";
                versal_thermal = "/thermal-zones/versal-thermal";
                temp_alert = "/thermal-zones/versal-thermal/trips/temp-alert";
                ot_crit = "/thermal-zones/versal-thermal/trips/ot-crit";
                versal_thermal_aie = "/thermal-zones/versal-aie-thermal";
                temp_alert_aie = "/thermal-zones/versal-aie-thermal/trips/temp-alert-aie";
                ot_crit_aie = "/thermal-zones/versal-aie-thermal/trips/ot-crit-aie";
                amba_apu = "/apu-bus";
                amba_rpu = "/rpu-bus";
                amba = "/axi";
                imux = "/axi/interrupt-multiplex";
                lpd_dma_chan0 = "/axi/dma-controller@ffa80000";
                lpd_dma_chan1 = "/axi/dma-controller@ffa90000";
                lpd_dma_chan2 = "/axi/dma-controller@ffaa0000";
                lpd_dma_chan3 = "/axi/dma-controller@ffab0000";
                lpd_dma_chan4 = "/axi/dma-controller@ffac0000";
                lpd_dma_chan5 = "/axi/dma-controller@ffad0000";
                lpd_dma_chan6 = "/axi/dma-controller@ffae0000";
                lpd_dma_chan7 = "/axi/dma-controller@ffaf0000";
                gpio0 = "/axi/gpio@ff0b0000";
                gpio1 = "/axi/gpio@f1020000";
                i2c0 = "/axi/i2c@ff020000";
                regulator_u50 = "/axi/i2c@ff020000/regulator@60";
                regulator_uXX = "/axi/i2c@ff020000/regulator@61";
                sensor_u30 = "/axi/i2c@ff020000/temp-sensor@1a";
                gpio_u43 = "/axi/i2c@ff020000/gpio@20";
                ina_u48 = "/axi/i2c@ff020000/power-sensor@40";
                ina_u49 = "/axi/i2c@ff020000/power-sensor@41";
                i2c1 = "/axi/i2c@ff030000";
                qsfp_power = "/axi/i2c@ff030000/gpio@21";
                i2c_qsfp1 = "/axi/i2c@ff030000/i2c-mux@70";
                qsfp1 = "/axi/i2c@ff030000/i2c-mux@70/i2c@0/gpio@20";
                qsfp2 = "/axi/i2c@ff030000/i2c-mux@70/i2c@2/gpio@20";
                i2c_qsfp3 = "/axi/i2c@ff030000/i2c-mux@71";
                qsfp3 = "/axi/i2c@ff030000/i2c-mux@71/i2c@0/gpio@20";
                qsfp4 = "/axi/i2c@ff030000/i2c-mux@71/i2c@2/gpio@20";
                pcie = "/axi/i2c@ff030000/i2c-mux@72";
                ocm = "/axi/memory-controller@ff960000";
                sdhci0 = "/axi/mmc@f1040000";
                serial0 = "/axi/serial@ff000000";
                serial1 = "/axi/serial@ff010000";
                ospi = "/axi/spi@f1010000";
                ospi_flash = "/axi/spi@f1010000/flash@0";
                spi0 = "/axi/spi@ff040000";
                sysmon0 = "/axi/sysmon@f1270000";
                ttc0 = "/axi/timer@ff0e0000";
                ttc1 = "/axi/timer@ff0f0000";
                ttc2 = "/axi/timer@ff100000";
                ttc3 = "/axi/timer@ff110000";
                dma0 = "/axi/pmcdma@f11c0000";
                dma1 = "/axi/pmcdma@f11d0000";
                pmc_trng = "/axi/pmc_trng@f1230000";
                pmc_cfi_cframe_0 = "/axi/cframe@f12d0000";
                pmc_cfu_apb_0 = "/axi/cfu_apb@f12b0000";
                pmc_ppu1_mdm_0 = "/axi/ppu1_mdm@f0310000";
                iomodule0 = "/axi/iomodule@f0280000";
                ipi_pmc = "/axi/mailbox@ff320000";
                ipi_pmc_to_ipi_0 = "/axi/mailbox@ff320000/child@ff330000";
                ipi_pmc_to_ipi_1 = "/axi/mailbox@ff320000/child@ff340000";
                ipi_pmc_to_ipi_2 = "/axi/mailbox@ff320000/child@ff350000";
                ipi_pmc_to_ipi_3 = "/axi/mailbox@ff320000/child@ff360000";
                ipi_pmc_to_ipi_4 = "/axi/mailbox@ff320000/child@ff370000";
                ipi_pmc_to_ipi_5 = "/axi/mailbox@ff320000/child@ff380000";
                ipi_pmc_to_ipi_6 = "/axi/mailbox@ff320000/child@ff3a0000";
                ipi_pmc_to_ipi_pmc = "/axi/mailbox@ff320000/child@ff320000";
                ipi_pmc_to_ipi_pmc_nobuf = "/axi/mailbox@ff320000/child@ff390000";
                ipi_pmc_to_ipi_psm = "/axi/mailbox@ff320000/child@ff310000";
                ipi_pmc_nobuf = "/axi/mailbox@ff390000";
                ipi_pmc_nobuf_to_ipi_0 = "/axi/mailbox@ff390000/child@ff330000";
                ipi_pmc_nobuf_to_ipi_1 = "/axi/mailbox@ff390000/child@ff340000";
                ipi_pmc_nobuf_to_ipi_2 = "/axi/mailbox@ff390000/child@ff350000";
                ipi_pmc_nobuf_to_ipi_3 = "/axi/mailbox@ff390000/child@ff360000";
                ipi_pmc_nobuf_to_ipi_4 = "/axi/mailbox@ff390000/child@ff370000";
                ipi_pmc_nobuf_to_ipi_5 = "/axi/mailbox@ff390000/child@ff380000";
                ipi_pmc_nobuf_to_ipi_6 = "/axi/mailbox@ff390000/child@ff3a0000";
                ipi_pmc_nobuf_to_ipi_pmc = "/axi/mailbox@ff390000/child@ff320000";
                ipi_pmc_nobuf_to_ipi_pmc_nobuf = "/axi/mailbox@ff390000/child@ff390000";
                ipi_pmc_nobuf_to_ipi_psm = "/axi/mailbox@ff390000/child@ff310000";
                versal_cips_0_pspmc_0_psv_pmc_cfi_cframe_1 = "/axi/versal_cips_0_pspmc_0_psv_pmc_cfi_cframe_1@f12d2000";
                versal_cips_0_pspmc_0_psv_pmc_cfi_cframe_10 = "/axi/versal_cips_0_pspmc_0_psv_pmc_cfi_cframe_10@f12e4000";
                versal_cips_0_pspmc_0_psv_pmc_cfi_cframe_11 = "/axi/versal_cips_0_pspmc_0_psv_pmc_cfi_cframe_11@f12e6000";
                versal_cips_0_pspmc_0_psv_pmc_cfi_cframe_12 = "/axi/versal_cips_0_pspmc_0_psv_pmc_cfi_cframe_12@f12e8000";
                versal_cips_0_pspmc_0_psv_pmc_cfi_cframe_13 = "/axi/versal_cips_0_pspmc_0_psv_pmc_cfi_cframe_13@f12ea000";
                versal_cips_0_pspmc_0_psv_pmc_cfi_cframe_14 = "/axi/versal_cips_0_pspmc_0_psv_pmc_cfi_cframe_14@f12ec000";
                versal_cips_0_pspmc_0_psv_pmc_cfi_cframe_2 = "/axi/versal_cips_0_pspmc_0_psv_pmc_cfi_cframe_2@f12d4000";
                versal_cips_0_pspmc_0_psv_pmc_cfi_cframe_3 = "/axi/versal_cips_0_pspmc_0_psv_pmc_cfi_cframe_3@f12d6000";
                versal_cips_0_pspmc_0_psv_pmc_cfi_cframe_4 = "/axi/versal_cips_0_pspmc_0_psv_pmc_cfi_cframe_4@f12d8000";
                versal_cips_0_pspmc_0_psv_pmc_cfi_cframe_5 = "/axi/versal_cips_0_pspmc_0_psv_pmc_cfi_cframe_5@f12da000";
                versal_cips_0_pspmc_0_psv_pmc_cfi_cframe_6 = "/axi/versal_cips_0_pspmc_0_psv_pmc_cfi_cframe_6@f12dc000";
                versal_cips_0_pspmc_0_psv_pmc_cfi_cframe_7 = "/axi/versal_cips_0_pspmc_0_psv_pmc_cfi_cframe_7@f12de000";
                versal_cips_0_pspmc_0_psv_pmc_cfi_cframe_8 = "/axi/versal_cips_0_pspmc_0_psv_pmc_cfi_cframe_8@f12e0000";
                versal_cips_0_pspmc_0_psv_pmc_cfi_cframe_9 = "/axi/versal_cips_0_pspmc_0_psv_pmc_cfi_cframe_9@f12e2000";
                versal_cips_0_pspmc_0_psv_pmc_cfi_cframe_bcast = "/axi/versal_cips_0_pspmc_0_psv_pmc_cfi_cframe_bcast@f12ee000";
                versal_cips_0_pspmc_0_psv_r5_0_atcm = "/axi/versal_cips_0_pspmc_0_psv_r5_0_atcm@0";
                versal_cips_0_pspmc_0_psv_r5_0_atcm_lockstep = "/axi/versal_cips_0_pspmc_0_psv_r5_0_atcm_lockstep@ffe10000";
                versal_cips_0_pspmc_0_psv_r5_0_btcm = "/axi/versal_cips_0_pspmc_0_psv_r5_0_btcm@20000";
                versal_cips_0_pspmc_0_psv_r5_0_btcm_lockstep = "/axi/versal_cips_0_pspmc_0_psv_r5_0_btcm_lockstep@ffe30000";
                versal_cips_0_pspmc_0_psv_r5_1_atcm = "/axi/versal_cips_0_pspmc_0_psv_r5_1_atcm@0";
                versal_cips_0_pspmc_0_psv_r5_1_btcm = "/axi/versal_cips_0_pspmc_0_psv_r5_1_btcm@20000";
                versal_cips_0_pspmc_0_psv_r5_tcm_ram_0 = "/axi/versal_cips_0_pspmc_0_psv_r5_tcm_ram_0@0";
                psv_r5_0_atcm_global = "/psv_r5_0_atcm_global@ffe00000";
                psv_r5_0_btcm_global = "/psv_r5_0_btcm_global@ffe20000";
                psv_r5_1_atcm_global = "/psv_r5_1_atcm_global@ffe90000";
                psv_r5_1_btcm_global = "/psv_r5_1_btcm_global@ffeb0000";
                amba_xppu = "/indirect-bus@1";
                amba_xmpu = "/indirect-bus@2";
                pl_alt_ref = "/pl-alt-ref";
                ref = "/ref";
                can0_clk = "/can0-clk";
                can1_clk = "/can1-clk";
                versal_firmware = "/firmware/versal-firmware";
                versal_clk = "/firmware/versal-firmware/clock-controller";
                zynqmp_power = "/firmware/versal-firmware/power-management";
                versal_reset = "/firmware/versal-firmware/reset-controller";
                pinctrl0 = "/firmware/versal-firmware/pinctrl";
                versal_sec_cfg = "/firmware/versal-firmware/versal-sec-cfg";
                bbram_zeroize = "/firmware/versal-firmware/versal-sec-cfg/nvmem-layout/bbram-zeroize@4";
                bbram_key = "/firmware/versal-firmware/versal-sec-cfg/nvmem-layout/bbram-key@10";
                bbram_usr = "/firmware/versal-firmware/versal-sec-cfg/nvmem-layout/bbram-usr@30";
                bbram_lock = "/firmware/versal-firmware/versal-sec-cfg/nvmem-layout/bbram-lock@48";
                user_key0 = "/firmware/versal-firmware/versal-sec-cfg/nvmem-layout/user-key@110";
                user_key1 = "/firmware/versal-firmware/versal-sec-cfg/nvmem-layout/user-key@130";
                user_key2 = "/firmware/versal-firmware/versal-sec-cfg/nvmem-layout/user-key@150";
                user_key3 = "/firmware/versal-firmware/versal-sec-cfg/nvmem-layout/user-key@170";
                user_key4 = "/firmware/versal-firmware/versal-sec-cfg/nvmem-layout/user-key@190";
                user_key5 = "/firmware/versal-firmware/versal-sec-cfg/nvmem-layout/user-key@1b0";
                user_key6 = "/firmware/versal-firmware/versal-sec-cfg/nvmem-layout/user-key@1d0";
                user_key7 = "/firmware/versal-firmware/versal-sec-cfg/nvmem-layout/user-key@1f0";
                amba_pl = "/amba_pl";
        };
};
